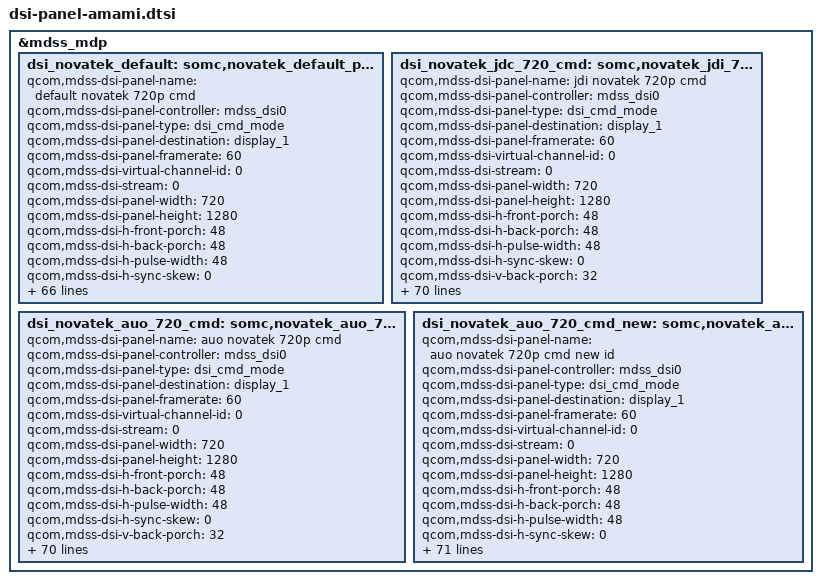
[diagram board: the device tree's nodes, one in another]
/* Copyright (c) 2012, Code Aurora Forum. All rights reserved.
 * Copyright (C) 2013-2014 Sony Mobile Communications AB.
 *
 * This program is free software; you can redistribute it and/or modify
 * it under the terms of the GNU General Public License version 2 and
 * only version 2 as published by the Free Software Foundation.
 *
 * This program is distributed in the hope that it will be useful,
 * but WITHOUT ANY WARRANTY; without even the implied warranty of
 * MERCHANTABILITY or FITNESS FOR A PARTICULAR PURPOSE.  See the
 * GNU General Public License for more details.
 */

&mdss_mdp {
	dsi_novatek_default: somc,novatek_default_panel {
		qcom,mdss-dsi-panel-name = "default novatek 720p cmd";
		qcom,mdss-dsi-panel-controller = <&mdss_dsi0>;
		qcom,mdss-dsi-panel-type = "dsi_cmd_mode";
		qcom,mdss-dsi-panel-destination = "display_1";
		qcom,mdss-dsi-panel-framerate = <60>;
		qcom,mdss-dsi-virtual-channel-id = <0>;
		qcom,mdss-dsi-stream = <0>;
		qcom,mdss-dsi-panel-width = <720>;
		qcom,mdss-dsi-panel-height = <1280>;
		qcom,mdss-dsi-h-front-porch = <48>;
		qcom,mdss-dsi-h-back-porch = <48>;
		qcom,mdss-dsi-h-pulse-width = <48>;
		qcom,mdss-dsi-h-sync-skew = <0>;
		qcom,mdss-dsi-v-back-porch = <32>;
		qcom,mdss-dsi-v-front-porch = <32>;
		qcom,mdss-dsi-v-pulse-width = <32>;
		qcom,mdss-dsi-h-left-border = <0>;
		qcom,mdss-dsi-h-right-border = <0>;
		qcom,mdss-dsi-v-top-border = <0>;
		qcom,mdss-dsi-v-bottom-border = <0>;
		qcom,mdss-dsi-bpp = <24>;
		qcom,mdss-dsi-underflow-color = <0x0>;
		qcom,mdss-dsi-border-color = <0>;
		somc,mdss-dsi-id-read-command = [06 01 00 01 05 00 02 A1 00];
		somc,mdss-dsi-early-init-command = [15 01 00 00 00 00 02 FF EE
				15 01 00 00 01 00 02 26 08
				15 01 00 00 00 00 02 26 00
				15 01 00 00 00 00 02 FF 00];
		somc,mdss-dsi-init-command = [15 01 00 00 00 00 02 BA 03
				15 01 00 00 00 00 02 C2 08
				15 01 00 00 00 00 02 FB 01
				15 01 00 00 00 00 02 FF 01
				15 01 00 00 00 00 02 75 00
				15 01 00 00 00 00 02 76 00
				15 01 00 00 00 00 02 77 00
				15 01 00 00 00 00 02 78 0F
				15 01 00 00 00 00 02 79 00
				15 01 00 00 00 00 02 7A 27
				15 01 00 00 00 00 02 7B 00
				15 01 00 00 00 00 02 7C 38
				15 01 00 00 00 00 02 7D 00
				15 01 00 00 00 00 02 7E 48
				15 01 00 00 00 00 02 7F 00
				15 01 00 00 00 00 02 80 57
				15 01 00 00 00 00 02 81 00
				15 01 00 00 00 00 02 82 64
				15 01 00 00 00 00 02 83 00
				15 01 00 00 00 00 02 84 72
				15 01 00 00 00 00 02 85 00
				15 01 00 00 00 00 02 86 7E
				15 01 00 00 00 00 02 87 00
				15 01 00 00 00 00 02 88 A5
				15 01 00 00 00 00 02 89 00
				15 01 00 00 00 00 02 8A C6
				15 01 00 00 00 00 02 8B 00
				15 01 00 00 00 00 02 8C FD
				15 01 00 00 00 00 02 8D 01
				15 01 00 00 00 00 02 8E 28
				15 01 00 00 00 00 02 8F 01
				15 01 00 00 00 00 02 90 71
				15 01 00 00 00 00 02 91 01
				15 01 00 00 00 00 02 92 AC
				15 01 00 00 00 00 02 93 01
				15 01 00 00 00 00 02 94 AD
				15 01 00 00 00 00 02 95 01
				15 01 00 00 00 00 02 96 E4
				15 01 00 00 00 00 02 97 02
				15 01 00 00 00 00 02 98 33
				15 01 00 00 00 00 02 99 02
				15 01 00 00 00 00 02 9A 75
				15 01 00 00 00 00 02 9B 02
				15 01 00 00 00 00 02 9C D0
				15 01 00 00 00 00 02 9D 03
				15 01 00 00 00 00 02 9E 09
				15 01 00 00 00 00 02 9F 03
				15 01 00 00 00 00 02 A0 33
				15 01 00 00 00 00 02 A2 03
				15 01 00 00 00 00 02 A3 3C
				15 01 00 00 00 00 02 A4 03
				15 01 00 00 00 00 02 A5 47
				15 01 00 00 00 00 02 A6 03
				15 01 00 00 00 00 02 A7 59
				15 01 00 00 00 00 02 A9 03
				15 01 00 00 00 00 02 AA 73
				15 01 00 00 00 00 02 AB 03
				15 01 00 00 00 00 02 AC 97
				15 01 00 00 00 00 02 AD 03
				15 01 00 00 00 00 02 AE BF
				15 01 00 00 00 00 02 AF 03
				15 01 00 00 00 00 02 B0 E9
				15 01 00 00 00 00 02 B1 03
				15 01 00 00 00 00 02 B2 FF
				15 01 00 00 00 00 02 B3 00
				15 01 00 00 00 00 02 B4 00
				15 01 00 00 00 00 02 B5 00
				15 01 00 00 00 00 02 B6 0F
				15 01 00 00 00 00 02 B7 00
				15 01 00 00 00 00 02 B8 27
				15 01 00 00 00 00 02 B9 00
				15 01 00 00 00 00 02 BA 38
				15 01 00 00 00 00 02 BB 00
				15 01 00 00 00 00 02 BC 48
				15 01 00 00 00 00 02 BD 00
				15 01 00 00 00 00 02 BE 57
				15 01 00 00 00 00 02 BF 00
				15 01 00 00 00 00 02 C0 64
				15 01 00 00 00 00 02 C1 00
				15 01 00 00 00 00 02 C2 72
				15 01 00 00 00 00 02 C3 00
				15 01 00 00 00 00 02 C4 7E
				15 01 00 00 00 00 02 C5 00
				15 01 00 00 00 00 02 C6 A5
				15 01 00 00 00 00 02 C7 00
				15 01 00 00 00 00 02 C8 C6
				15 01 00 00 00 00 02 C9 00
				15 01 00 00 00 00 02 CA FD
				15 01 00 00 00 00 02 CB 01
				15 01 00 00 00 00 02 CC 28
				15 01 00 00 00 00 02 CD 01
				15 01 00 00 00 00 02 CE 71
				15 01 00 00 00 00 02 CF 01
				15 01 00 00 00 00 02 D0 AC
				15 01 00 00 00 00 02 D1 01
				15 01 00 00 00 00 02 D2 AD
				15 01 00 00 00 00 02 D3 01
				15 01 00 00 00 00 02 D4 E4
				15 01 00 00 00 00 02 D5 02
				15 01 00 00 00 00 02 D6 33
				15 01 00 00 00 00 02 D7 02
				15 01 00 00 00 00 02 D8 75
				15 01 00 00 00 00 02 D9 02
				15 01 00 00 00 00 02 DA D0
				15 01 00 00 00 00 02 DB 03
				15 01 00 00 00 00 02 DC 09
				15 01 00 00 00 00 02 DD 03
				15 01 00 00 00 00 02 DE 33
				15 01 00 00 00 00 02 DF 03
				15 01 00 00 00 00 02 E0 3C
				15 01 00 00 00 00 02 E1 03
				15 01 00 00 00 00 02 E2 47
				15 01 00 00 00 00 02 E3 03
				15 01 00 00 00 00 02 E4 59
				15 01 00 00 00 00 02 E5 03
				15 01 00 00 00 00 02 E6 73
				15 01 00 00 00 00 02 E7 03
				15 01 00 00 00 00 02 E8 97
				15 01 00 00 00 00 02 E9 03
				15 01 00 00 00 00 02 EA BF
				15 01 00 00 00 00 02 EB 03
				15 01 00 00 00 00 02 EC E9
				15 01 00 00 00 00 02 ED 03
				15 01 00 00 00 00 02 EE FF
				15 01 00 00 00 00 02 EF 00
				15 01 00 00 00 00 02 F0 80
				15 01 00 00 00 00 02 F1 00
				15 01 00 00 00 00 02 F2 84
				15 01 00 00 00 00 02 F3 00
				15 01 00 00 00 00 02 F4 8F
				15 01 00 00 00 00 02 F5 00
				15 01 00 00 00 00 02 F6 98
				15 01 00 00 00 00 02 F7 00
				15 01 00 00 00 00 02 F8 A1
				15 01 00 00 00 00 02 F9 00
				15 01 00 00 00 00 02 FA AA
				15 01 00 00 00 00 02 FF 02
				15 01 00 00 00 00 02 00 00
				15 01 00 00 00 00 02 01 B3
				15 01 00 00 00 00 02 02 00
				15 01 00 00 00 00 02 03 BB
				15 01 00 00 00 00 02 04 00
				15 01 00 00 00 00 02 05 C2
				15 01 00 00 00 00 02 06 00
				15 01 00 00 00 00 02 07 DE
				15 01 00 00 00 00 02 08 00
				15 01 00 00 00 00 02 09 F7
				15 01 00 00 00 00 02 0A 01
				15 01 00 00 00 00 02 0B 22
				15 01 00 00 00 00 02 0C 01
				15 01 00 00 00 00 02 0D 48
				15 01 00 00 00 00 02 0E 01
				15 01 00 00 00 00 02 0F 86
				15 01 00 00 00 00 02 10 01
				15 01 00 00 00 00 02 11 BB
				15 01 00 00 00 00 02 12 01
				15 01 00 00 00 00 02 13 BD
				15 01 00 00 00 00 02 14 01
				15 01 00 00 00 00 02 15 EE
				15 01 00 00 00 00 02 16 02
				15 01 00 00 00 00 02 17 39
				15 01 00 00 00 00 02 18 02
				15 01 00 00 00 00 02 19 79
				15 01 00 00 00 00 02 1A 02
				15 01 00 00 00 00 02 1B CB
				15 01 00 00 00 00 02 1C 03
				15 01 00 00 00 00 02 1D 00
				15 01 00 00 00 00 02 1E 03
				15 01 00 00 00 00 02 1F 2E
				15 01 00 00 00 00 02 20 03
				15 01 00 00 00 00 02 21 3D
				15 01 00 00 00 00 02 22 03
				15 01 00 00 00 00 02 23 4E
				15 01 00 00 00 00 02 24 03
				15 01 00 00 00 00 02 25 62
				15 01 00 00 00 00 02 26 03
				15 01 00 00 00 00 02 27 7A
				15 01 00 00 00 00 02 28 03
				15 01 00 00 00 00 02 29 97
				15 01 00 00 00 00 02 2A 03
				15 01 00 00 00 00 02 2B BB
				15 01 00 00 00 00 02 2D 03
				15 01 00 00 00 00 02 2F E7
				15 01 00 00 00 00 02 30 03
				15 01 00 00 00 00 02 31 FF
				15 01 00 00 00 00 02 32 00
				15 01 00 00 00 00 02 33 80
				15 01 00 00 00 00 02 34 00
				15 01 00 00 00 00 02 35 84
				15 01 00 00 00 00 02 36 00
				15 01 00 00 00 00 02 37 8F
				15 01 00 00 00 00 02 38 00
				15 01 00 00 00 00 02 39 98
				15 01 00 00 00 00 02 3A 00
				15 01 00 00 00 00 02 3B A1
				15 01 00 00 00 00 02 3D 00
				15 01 00 00 00 00 02 3F AA
				15 01 00 00 00 00 02 40 00
				15 01 00 00 00 00 02 41 B3
				15 01 00 00 00 00 02 42 00
				15 01 00 00 00 00 02 43 BB
				15 01 00 00 00 00 02 44 00
				15 01 00 00 00 00 02 45 C2
				15 01 00 00 00 00 02 46 00
				15 01 00 00 00 00 02 47 DE
				15 01 00 00 00 00 02 48 00
				15 01 00 00 00 00 02 49 F7
				15 01 00 00 00 00 02 4A 01
				15 01 00 00 00 00 02 4B 22
				15 01 00 00 00 00 02 4C 01
				15 01 00 00 00 00 02 4D 48
				15 01 00 00 00 00 02 4E 01
				15 01 00 00 00 00 02 4F 86
				15 01 00 00 00 00 02 50 01
				15 01 00 00 00 00 02 51 BB
				15 01 00 00 00 00 02 52 01
				15 01 00 00 00 00 02 53 BD
				15 01 00 00 00 00 02 54 01
				15 01 00 00 00 00 02 55 EE
				15 01 00 00 00 00 02 56 02
				15 01 00 00 00 00 02 58 39
				15 01 00 00 00 00 02 59 02
				15 01 00 00 00 00 02 5A 79
				15 01 00 00 00 00 02 5B 02
				15 01 00 00 00 00 02 5C CB
				15 01 00 00 00 00 02 5D 03
				15 01 00 00 00 00 02 5E 00
				15 01 00 00 00 00 02 5F 03
				15 01 00 00 00 00 02 60 2E
				15 01 00 00 00 00 02 61 03
				15 01 00 00 00 00 02 62 3D
				15 01 00 00 00 00 02 63 03
				15 01 00 00 00 00 02 64 4E
				15 01 00 00 00 00 02 65 03
				15 01 00 00 00 00 02 66 62
				15 01 00 00 00 00 02 67 03
				15 01 00 00 00 00 02 68 7A
				15 01 00 00 00 00 02 69 03
				15 01 00 00 00 00 02 6A 97
				15 01 00 00 00 00 02 6B 03
				15 01 00 00 00 00 02 6C BB
				15 01 00 00 00 00 02 6D 03
				15 01 00 00 00 00 02 6E E7
				15 01 00 00 00 00 02 6F 03
				15 01 00 00 00 00 02 70 FF
				15 01 00 00 00 00 02 71 00
				15 01 00 00 00 00 02 72 00
				15 01 00 00 00 00 02 73 00
				15 01 00 00 00 00 02 74 0E
				15 01 00 00 00 00 02 75 00
				15 01 00 00 00 00 02 76 21
				15 01 00 00 00 00 02 77 00
				15 01 00 00 00 00 02 78 2F
				15 01 00 00 00 00 02 79 00
				15 01 00 00 00 00 02 7A 3E
				15 01 00 00 00 00 02 7B 00
				15 01 00 00 00 00 02 7C 4C
				15 01 00 00 00 00 02 7D 00
				15 01 00 00 00 00 02 7E 5A
				15 01 00 00 00 00 02 7F 00
				15 01 00 00 00 00 02 80 67
				15 01 00 00 00 00 02 81 00
				15 01 00 00 00 00 02 82 71
				15 01 00 00 00 00 02 83 00
				15 01 00 00 00 00 02 84 97
				15 01 00 00 00 00 02 85 00
				15 01 00 00 00 00 02 86 B8
				15 01 00 00 00 00 02 87 00
				15 01 00 00 00 00 02 88 F1
				15 01 00 00 00 00 02 89 01
				15 01 00 00 00 00 02 8A 1C
				15 01 00 00 00 00 02 8B 01
				15 01 00 00 00 00 02 8C 63
				15 01 00 00 00 00 02 8D 01
				15 01 00 00 00 00 02 8E A0
				15 01 00 00 00 00 02 8F 01
				15 01 00 00 00 00 02 90 A1
				15 01 00 00 00 00 02 91 01
				15 01 00 00 00 00 02 92 D6
				15 01 00 00 00 00 02 93 02
				15 01 00 00 00 00 02 94 24
				15 01 00 00 00 00 02 95 02
				15 01 00 00 00 00 02 96 61
				15 01 00 00 00 00 02 97 02
				15 01 00 00 00 00 02 98 B7
				15 01 00 00 00 00 02 99 02
				15 01 00 00 00 00 02 9A F4
				15 01 00 00 00 00 02 9B 03
				15 01 00 00 00 00 02 9C 24
				15 01 00 00 00 00 02 9D 03
				15 01 00 00 00 00 02 9E 36
				15 01 00 00 00 00 02 9F 03
				15 01 00 00 00 00 02 A0 4B
				15 01 00 00 00 00 02 A2 03
				15 01 00 00 00 00 02 A3 63
				15 01 00 00 00 00 02 A4 03
				15 01 00 00 00 00 02 A5 7D
				15 01 00 00 00 00 02 A6 03
				15 01 00 00 00 00 02 A7 9B
				15 01 00 00 00 00 02 A9 03
				15 01 00 00 00 00 02 AA BF
				15 01 00 00 00 00 02 AB 03
				15 01 00 00 00 00 02 AC E8
				15 01 00 00 00 00 02 AD 03
				15 01 00 00 00 00 02 AE FF
				15 01 00 00 00 00 02 AF 00
				15 01 00 00 00 00 02 B0 00
				15 01 00 00 00 00 02 B1 00
				15 01 00 00 00 00 02 B2 0E
				15 01 00 00 00 00 02 B3 00
				15 01 00 00 00 00 02 B4 21
				15 01 00 00 00 00 02 B5 00
				15 01 00 00 00 00 02 B6 2F
				15 01 00 00 00 00 02 B7 00
				15 01 00 00 00 00 02 B8 3E
				15 01 00 00 00 00 02 B9 00
				15 01 00 00 00 00 02 BA 4C
				15 01 00 00 00 00 02 BB 00
				15 01 00 00 00 00 02 BC 5A
				15 01 00 00 00 00 02 BD 00
				15 01 00 00 00 00 02 BE 67
				15 01 00 00 00 00 02 BF 00
				15 01 00 00 00 00 02 C0 71
				15 01 00 00 00 00 02 C1 00
				15 01 00 00 00 00 02 C2 97
				15 01 00 00 00 00 02 C3 00
				15 01 00 00 00 00 02 C4 B8
				15 01 00 00 00 00 02 C5 00
				15 01 00 00 00 00 02 C6 F1
				15 01 00 00 00 00 02 C7 01
				15 01 00 00 00 00 02 C8 1C
				15 01 00 00 00 00 02 C9 01
				15 01 00 00 00 00 02 CA 63
				15 01 00 00 00 00 02 CB 01
				15 01 00 00 00 00 02 CC A0
				15 01 00 00 00 00 02 CD 01
				15 01 00 00 00 00 02 CE A1
				15 01 00 00 00 00 02 CF 01
				15 01 00 00 00 00 02 D0 D6
				15 01 00 00 00 00 02 D1 02
				15 01 00 00 00 00 02 D2 24
				15 01 00 00 00 00 02 D3 02
				15 01 00 00 00 00 02 D4 61
				15 01 00 00 00 00 02 D5 02
				15 01 00 00 00 00 02 D6 B7
				15 01 00 00 00 00 02 D7 02
				15 01 00 00 00 00 02 D8 F4
				15 01 00 00 00 00 02 D9 03
				15 01 00 00 00 00 02 DA 24
				15 01 00 00 00 00 02 DB 03
				15 01 00 00 00 00 02 DC 36
				15 01 00 00 00 00 02 DD 03
				15 01 00 00 00 00 02 DE 4B
				15 01 00 00 00 00 02 DF 03
				15 01 00 00 00 00 02 E0 63
				15 01 00 00 00 00 02 E1 03
				15 01 00 00 00 00 02 E2 7D
				15 01 00 00 00 00 02 E3 03
				15 01 00 00 00 00 02 E4 9B
				15 01 00 00 00 00 02 E5 03
				15 01 00 00 00 00 02 E6 BF
				15 01 00 00 00 00 02 E7 03
				15 01 00 00 00 00 02 E8 E8
				15 01 00 00 00 00 02 E9 03
				15 01 00 00 00 00 02 EA FF
				15 01 00 00 00 00 02 FF 01
				15 01 00 00 00 00 02 FB 01
				15 01 00 00 00 00 02 FF 02
				15 01 00 00 00 00 02 FB 01
				15 01 00 00 00 00 02 FF EE
				15 01 00 00 00 00 02 12 50
				15 01 00 00 00 00 02 13 02
				15 01 00 00 00 00 02 6A 60
				15 01 00 00 00 00 02 FB 01
				15 01 00 00 00 00 02 FF 00
				15 01 00 00 0A 00 02 35 00
				05 01 00 00 00 00 01 11];
		qcom,mdss-dsi-on-command = [05 01 00 00 00 00 01 29];
		qcom,mdss-dsi-off-command = [05 01 00 00 00 00 01 28
				05 01 00 00 78 00 01 10];
		qcom,mdss-dsi-on-command-state = "dsi_hs_mode";
		qcom,mdss-dsi-off-command-state = "dsi_hs_mode";

		somc,mdss-dsi-cabc-early-on-command = [15 01 00 00 00 00 02 FF 04
				15 01 00 00 00 00 02 2A 84
				15 01 00 00 00 00 02 29 99
				15 01 00 00 00 00 02 28 99
				15 01 00 00 00 00 02 27 99
				15 01 00 00 00 00 02 26 AA
				15 01 00 00 00 00 02 25 BB
				15 01 00 00 00 00 02 24 CC
				15 01 00 00 00 00 02 23 DD
				15 01 00 00 00 00 02 22 EE
				15 01 00 00 00 00 02 21 FF
				15 01 00 00 00 00 02 0A 03
				15 01 00 00 00 00 02 32 64
				15 01 00 00 00 00 02 FB 01
				15 01 00 00 00 00 02 FF 00
				15 01 00 00 00 00 02 51 FF
				15 01 00 00 00 00 02 53 2C
				15 01 00 00 00 00 02 55 03];
		somc,mdss-dsi-cabc-late-off-command = [15 01 00 00 00 00 02 51 00
				15 01 00 00 00 00 02 53 00
				15 01 00 00 00 00 02 55 00];
		somc,mdss-dsi-cabc-enabled = <1>;

		qcom,mdss-dsi-h-sync-pulse = <1>;
		qcom,mdss-dsi-traffic-mode = "non_burst_sync_event";
		qcom,mdss-dsi-bllp-eof-power-mode;
		qcom,mdss-dsi-bllp-power-mode;
		qcom,mdss-dsi-lane-0-state;
		qcom,mdss-dsi-lane-1-state;
		qcom,mdss-dsi-lane-2-state;
		qcom,mdss-dsi-lane-3-state;
		qcom,mdss-dsi-te-pin-select = <1>;
		qcom,mdss-dsi-te-v-sync-rd-ptr-irq-line = <0x2c>;
		qcom,mdss-dsi-te-v-sync-continue-lines = <0x3c>;
		qcom,mdss-dsi-te-dcs-command = <1>;
		qcom,mdss-dsi-te-check-enable;
		qcom,mdss-dsi-te-using-te-pin;
		qcom,mdss-dsi-panel-timings = [7a 1a 12 00 3e 42 16 20 14 03 04 00];
		qcom,mdss-dsi-t-clk-post = <0x0c>;
		qcom,mdss-dsi-t-clk-pre = <0x1a>;
		qcom,mdss-dsi-bl-min-level = <1>;
		qcom,mdss-dsi-bl-max-level = <4095>;
		qcom,mdss-dsi-dma-trigger = "trigger_sw";
		qcom,mdss-dsi-mdp-trigger = "none";
		qcom,mdss-dsi-bl-pmic-control-type = "bl_ctrl_wled";
		qcom,mdss-dsi-pan-enable-dynamic-fps;
		qcom,mdss-dsi-pan-fps-update = "dfps_suspend_resume_mode";
		qcom,mdss-dsi-reset-sequence = <1 20>, <0 200>, <1 20>;

		qcom,mdss-dsi-panel-clockrate = <428000000>;
		somc,panel-id = [ff];
		somc,panel-detect = <1>;
		somc,driver-ic = <2>;
		somc,mdss-phy-size-mm = <53 94>;
		somc,mdss-dsi-lane-config = [00 c2 45 00 00 00 00 01 75
				00 c2 45 00 00 00 00 01 75
				00 c2 45 00 00 00 00 01 75
				00 c2 45 00 00 00 00 01 75
				00 02 45 00 00 00 00 01 97];
		somc,mdss-dsi-disp-on-in-hs = <0>;
		somc,mdss-dsi-init-from-begin = <1>;
	};

	dsi_novatek_jdc_720_cmd: somc,novatek_jdi_720p_panel {
		qcom,mdss-dsi-panel-name = "jdi novatek 720p cmd";
		qcom,mdss-dsi-panel-controller = <&mdss_dsi0>;
		qcom,mdss-dsi-panel-type = "dsi_cmd_mode";
		qcom,mdss-dsi-panel-destination = "display_1";
		qcom,mdss-dsi-panel-framerate = <60>;
		qcom,mdss-dsi-virtual-channel-id = <0>;
		qcom,mdss-dsi-stream = <0>;
		qcom,mdss-dsi-panel-width = <720>;
		qcom,mdss-dsi-panel-height = <1280>;
		qcom,mdss-dsi-h-front-porch = <48>;
		qcom,mdss-dsi-h-back-porch = <48>;
		qcom,mdss-dsi-h-pulse-width = <48>;
		qcom,mdss-dsi-h-sync-skew = <0>;
		qcom,mdss-dsi-v-back-porch = <32>;
		qcom,mdss-dsi-v-front-porch = <32>;
		qcom,mdss-dsi-v-pulse-width = <32>;
		qcom,mdss-dsi-h-left-border = <0>;
		qcom,mdss-dsi-h-right-border = <0>;
		qcom,mdss-dsi-v-top-border = <0>;
		qcom,mdss-dsi-v-bottom-border = <0>;
		qcom,mdss-dsi-bpp = <24>;
		qcom,mdss-dsi-underflow-color = <0x0>;
		qcom,mdss-dsi-border-color = <0>;
		somc,mdss-dsi-id-read-command = [06 01 00 01 05 00 02 A1 00];
		somc,mdss-dsi-early-init-command = [15 01 00 00 00 00 02 FF EE
				15 01 00 00 01 00 02 26 08
				15 01 00 00 00 00 02 26 00
				15 01 00 00 00 00 02 FF 00];
		somc,mdss-dsi-init-command = [15 01 00 00 00 00 02 BA 03
				15 01 00 00 00 00 02 C2 08
				15 01 00 00 00 00 02 FB 01
				15 01 00 00 00 00 02 FF 01
				15 01 00 00 00 00 02 75 00
				15 01 00 00 00 00 02 76 00
				15 01 00 00 00 00 02 77 00
				15 01 00 00 00 00 02 78 0F
				15 01 00 00 00 00 02 79 00
				15 01 00 00 00 00 02 7A 27
				15 01 00 00 00 00 02 7B 00
				15 01 00 00 00 00 02 7C 38
				15 01 00 00 00 00 02 7D 00
				15 01 00 00 00 00 02 7E 48
				15 01 00 00 00 00 02 7F 00
				15 01 00 00 00 00 02 80 57
				15 01 00 00 00 00 02 81 00
				15 01 00 00 00 00 02 82 64
				15 01 00 00 00 00 02 83 00
				15 01 00 00 00 00 02 84 72
				15 01 00 00 00 00 02 85 00
				15 01 00 00 00 00 02 86 7E
				15 01 00 00 00 00 02 87 00
				15 01 00 00 00 00 02 88 A5
				15 01 00 00 00 00 02 89 00
				15 01 00 00 00 00 02 8A C6
				15 01 00 00 00 00 02 8B 00
				15 01 00 00 00 00 02 8C FD
				15 01 00 00 00 00 02 8D 01
				15 01 00 00 00 00 02 8E 28
				15 01 00 00 00 00 02 8F 01
				15 01 00 00 00 00 02 90 71
				15 01 00 00 00 00 02 91 01
				15 01 00 00 00 00 02 92 AC
				15 01 00 00 00 00 02 93 01
				15 01 00 00 00 00 02 94 AD
				15 01 00 00 00 00 02 95 01
				15 01 00 00 00 00 02 96 E4
				15 01 00 00 00 00 02 97 02
				15 01 00 00 00 00 02 98 33
				15 01 00 00 00 00 02 99 02
				15 01 00 00 00 00 02 9A 75
				15 01 00 00 00 00 02 9B 02
				15 01 00 00 00 00 02 9C D0
				15 01 00 00 00 00 02 9D 03
				15 01 00 00 00 00 02 9E 09
				15 01 00 00 00 00 02 9F 03
				15 01 00 00 00 00 02 A0 33
				15 01 00 00 00 00 02 A2 03
				15 01 00 00 00 00 02 A3 3C
				15 01 00 00 00 00 02 A4 03
				15 01 00 00 00 00 02 A5 47
				15 01 00 00 00 00 02 A6 03
				15 01 00 00 00 00 02 A7 59
				15 01 00 00 00 00 02 A9 03
				15 01 00 00 00 00 02 AA 73
				15 01 00 00 00 00 02 AB 03
				15 01 00 00 00 00 02 AC 97
				15 01 00 00 00 00 02 AD 03
				15 01 00 00 00 00 02 AE BF
				15 01 00 00 00 00 02 AF 03
				15 01 00 00 00 00 02 B0 E9
				15 01 00 00 00 00 02 B1 03
				15 01 00 00 00 00 02 B2 FF
				15 01 00 00 00 00 02 B3 00
				15 01 00 00 00 00 02 B4 00
				15 01 00 00 00 00 02 B5 00
				15 01 00 00 00 00 02 B6 0F
				15 01 00 00 00 00 02 B7 00
				15 01 00 00 00 00 02 B8 27
				15 01 00 00 00 00 02 B9 00
				15 01 00 00 00 00 02 BA 38
				15 01 00 00 00 00 02 BB 00
				15 01 00 00 00 00 02 BC 48
				15 01 00 00 00 00 02 BD 00
				15 01 00 00 00 00 02 BE 57
				15 01 00 00 00 00 02 BF 00
				15 01 00 00 00 00 02 C0 64
				15 01 00 00 00 00 02 C1 00
				15 01 00 00 00 00 02 C2 72
				15 01 00 00 00 00 02 C3 00
				15 01 00 00 00 00 02 C4 7E
				15 01 00 00 00 00 02 C5 00
				15 01 00 00 00 00 02 C6 A5
				15 01 00 00 00 00 02 C7 00
				15 01 00 00 00 00 02 C8 C6
				15 01 00 00 00 00 02 C9 00
				15 01 00 00 00 00 02 CA FD
				15 01 00 00 00 00 02 CB 01
				15 01 00 00 00 00 02 CC 28
				15 01 00 00 00 00 02 CD 01
				15 01 00 00 00 00 02 CE 71
				15 01 00 00 00 00 02 CF 01
				15 01 00 00 00 00 02 D0 AC
				15 01 00 00 00 00 02 D1 01
				15 01 00 00 00 00 02 D2 AD
				15 01 00 00 00 00 02 D3 01
				15 01 00 00 00 00 02 D4 E4
				15 01 00 00 00 00 02 D5 02
				15 01 00 00 00 00 02 D6 33
				15 01 00 00 00 00 02 D7 02
				15 01 00 00 00 00 02 D8 75
				15 01 00 00 00 00 02 D9 02
				15 01 00 00 00 00 02 DA D0
				15 01 00 00 00 00 02 DB 03
				15 01 00 00 00 00 02 DC 09
				15 01 00 00 00 00 02 DD 03
				15 01 00 00 00 00 02 DE 33
				15 01 00 00 00 00 02 DF 03
				15 01 00 00 00 00 02 E0 3C
				15 01 00 00 00 00 02 E1 03
				15 01 00 00 00 00 02 E2 47
				15 01 00 00 00 00 02 E3 03
				15 01 00 00 00 00 02 E4 59
				15 01 00 00 00 00 02 E5 03
				15 01 00 00 00 00 02 E6 73
				15 01 00 00 00 00 02 E7 03
				15 01 00 00 00 00 02 E8 97
				15 01 00 00 00 00 02 E9 03
				15 01 00 00 00 00 02 EA BF
				15 01 00 00 00 00 02 EB 03
				15 01 00 00 00 00 02 EC E9
				15 01 00 00 00 00 02 ED 03
				15 01 00 00 00 00 02 EE FF
				15 01 00 00 00 00 02 EF 00
				15 01 00 00 00 00 02 F0 80
				15 01 00 00 00 00 02 F1 00
				15 01 00 00 00 00 02 F2 84
				15 01 00 00 00 00 02 F3 00
				15 01 00 00 00 00 02 F4 8F
				15 01 00 00 00 00 02 F5 00
				15 01 00 00 00 00 02 F6 98
				15 01 00 00 00 00 02 F7 00
				15 01 00 00 00 00 02 F8 A1
				15 01 00 00 00 00 02 F9 00
				15 01 00 00 00 00 02 FA AA
				15 01 00 00 00 00 02 FF 02
				15 01 00 00 00 00 02 00 00
				15 01 00 00 00 00 02 01 B3
				15 01 00 00 00 00 02 02 00
				15 01 00 00 00 00 02 03 BB
				15 01 00 00 00 00 02 04 00
				15 01 00 00 00 00 02 05 C2
				15 01 00 00 00 00 02 06 00
				15 01 00 00 00 00 02 07 DE
				15 01 00 00 00 00 02 08 00
				15 01 00 00 00 00 02 09 F7
				15 01 00 00 00 00 02 0A 01
				15 01 00 00 00 00 02 0B 22
				15 01 00 00 00 00 02 0C 01
				15 01 00 00 00 00 02 0D 48
				15 01 00 00 00 00 02 0E 01
				15 01 00 00 00 00 02 0F 86
				15 01 00 00 00 00 02 10 01
				15 01 00 00 00 00 02 11 BB
				15 01 00 00 00 00 02 12 01
				15 01 00 00 00 00 02 13 BD
				15 01 00 00 00 00 02 14 01
				15 01 00 00 00 00 02 15 EE
				15 01 00 00 00 00 02 16 02
				15 01 00 00 00 00 02 17 39
				15 01 00 00 00 00 02 18 02
				15 01 00 00 00 00 02 19 79
				15 01 00 00 00 00 02 1A 02
				15 01 00 00 00 00 02 1B CB
				15 01 00 00 00 00 02 1C 03
				15 01 00 00 00 00 02 1D 00
				15 01 00 00 00 00 02 1E 03
				15 01 00 00 00 00 02 1F 2E
				15 01 00 00 00 00 02 20 03
				15 01 00 00 00 00 02 21 3D
				15 01 00 00 00 00 02 22 03
				15 01 00 00 00 00 02 23 4E
				15 01 00 00 00 00 02 24 03
				15 01 00 00 00 00 02 25 62
				15 01 00 00 00 00 02 26 03
				15 01 00 00 00 00 02 27 7A
				15 01 00 00 00 00 02 28 03
				15 01 00 00 00 00 02 29 97
				15 01 00 00 00 00 02 2A 03
				15 01 00 00 00 00 02 2B BB
				15 01 00 00 00 00 02 2D 03
				15 01 00 00 00 00 02 2F E7
				15 01 00 00 00 00 02 30 03
				15 01 00 00 00 00 02 31 FF
				15 01 00 00 00 00 02 32 00
				15 01 00 00 00 00 02 33 80
				15 01 00 00 00 00 02 34 00
				15 01 00 00 00 00 02 35 84
				15 01 00 00 00 00 02 36 00
				15 01 00 00 00 00 02 37 8F
				15 01 00 00 00 00 02 38 00
				15 01 00 00 00 00 02 39 98
				15 01 00 00 00 00 02 3A 00
				15 01 00 00 00 00 02 3B A1
				15 01 00 00 00 00 02 3D 00
				15 01 00 00 00 00 02 3F AA
				15 01 00 00 00 00 02 40 00
				15 01 00 00 00 00 02 41 B3
				15 01 00 00 00 00 02 42 00
				15 01 00 00 00 00 02 43 BB
				15 01 00 00 00 00 02 44 00
				15 01 00 00 00 00 02 45 C2
				15 01 00 00 00 00 02 46 00
				15 01 00 00 00 00 02 47 DE
				15 01 00 00 00 00 02 48 00
				15 01 00 00 00 00 02 49 F7
				15 01 00 00 00 00 02 4A 01
				15 01 00 00 00 00 02 4B 22
				15 01 00 00 00 00 02 4C 01
				15 01 00 00 00 00 02 4D 48
				15 01 00 00 00 00 02 4E 01
				15 01 00 00 00 00 02 4F 86
				15 01 00 00 00 00 02 50 01
				15 01 00 00 00 00 02 51 BB
				15 01 00 00 00 00 02 52 01
				15 01 00 00 00 00 02 53 BD
				15 01 00 00 00 00 02 54 01
				15 01 00 00 00 00 02 55 EE
				15 01 00 00 00 00 02 56 02
				15 01 00 00 00 00 02 58 39
				15 01 00 00 00 00 02 59 02
				15 01 00 00 00 00 02 5A 79
				15 01 00 00 00 00 02 5B 02
				15 01 00 00 00 00 02 5C CB
				15 01 00 00 00 00 02 5D 03
				15 01 00 00 00 00 02 5E 00
				15 01 00 00 00 00 02 5F 03
				15 01 00 00 00 00 02 60 2E
				15 01 00 00 00 00 02 61 03
				15 01 00 00 00 00 02 62 3D
				15 01 00 00 00 00 02 63 03
				15 01 00 00 00 00 02 64 4E
				15 01 00 00 00 00 02 65 03
				15 01 00 00 00 00 02 66 62
				15 01 00 00 00 00 02 67 03
				15 01 00 00 00 00 02 68 7A
				15 01 00 00 00 00 02 69 03
				15 01 00 00 00 00 02 6A 97
				15 01 00 00 00 00 02 6B 03
				15 01 00 00 00 00 02 6C BB
				15 01 00 00 00 00 02 6D 03
				15 01 00 00 00 00 02 6E E7
				15 01 00 00 00 00 02 6F 03
				15 01 00 00 00 00 02 70 FF
				15 01 00 00 00 00 02 71 00
				15 01 00 00 00 00 02 72 00
				15 01 00 00 00 00 02 73 00
				15 01 00 00 00 00 02 74 0E
				15 01 00 00 00 00 02 75 00
				15 01 00 00 00 00 02 76 21
				15 01 00 00 00 00 02 77 00
				15 01 00 00 00 00 02 78 2F
				15 01 00 00 00 00 02 79 00
				15 01 00 00 00 00 02 7A 3E
				15 01 00 00 00 00 02 7B 00
				15 01 00 00 00 00 02 7C 4C
				15 01 00 00 00 00 02 7D 00
				15 01 00 00 00 00 02 7E 5A
				15 01 00 00 00 00 02 7F 00
				15 01 00 00 00 00 02 80 67
				15 01 00 00 00 00 02 81 00
				15 01 00 00 00 00 02 82 71
				15 01 00 00 00 00 02 83 00
				15 01 00 00 00 00 02 84 97
				15 01 00 00 00 00 02 85 00
				15 01 00 00 00 00 02 86 B8
				15 01 00 00 00 00 02 87 00
				15 01 00 00 00 00 02 88 F1
				15 01 00 00 00 00 02 89 01
				15 01 00 00 00 00 02 8A 1C
				15 01 00 00 00 00 02 8B 01
				15 01 00 00 00 00 02 8C 63
				15 01 00 00 00 00 02 8D 01
				15 01 00 00 00 00 02 8E A0
				15 01 00 00 00 00 02 8F 01
				15 01 00 00 00 00 02 90 A1
				15 01 00 00 00 00 02 91 01
				15 01 00 00 00 00 02 92 D6
				15 01 00 00 00 00 02 93 02
				15 01 00 00 00 00 02 94 24
				15 01 00 00 00 00 02 95 02
				15 01 00 00 00 00 02 96 61
				15 01 00 00 00 00 02 97 02
				15 01 00 00 00 00 02 98 B7
				15 01 00 00 00 00 02 99 02
				15 01 00 00 00 00 02 9A F4
				15 01 00 00 00 00 02 9B 03
				15 01 00 00 00 00 02 9C 24
				15 01 00 00 00 00 02 9D 03
				15 01 00 00 00 00 02 9E 36
				15 01 00 00 00 00 02 9F 03
				15 01 00 00 00 00 02 A0 4B
				15 01 00 00 00 00 02 A2 03
				15 01 00 00 00 00 02 A3 63
				15 01 00 00 00 00 02 A4 03
				15 01 00 00 00 00 02 A5 7D
				15 01 00 00 00 00 02 A6 03
				15 01 00 00 00 00 02 A7 9B
				15 01 00 00 00 00 02 A9 03
				15 01 00 00 00 00 02 AA BF
				15 01 00 00 00 00 02 AB 03
				15 01 00 00 00 00 02 AC E8
				15 01 00 00 00 00 02 AD 03
				15 01 00 00 00 00 02 AE FF
				15 01 00 00 00 00 02 AF 00
				15 01 00 00 00 00 02 B0 00
				15 01 00 00 00 00 02 B1 00
				15 01 00 00 00 00 02 B2 0E
				15 01 00 00 00 00 02 B3 00
				15 01 00 00 00 00 02 B4 21
				15 01 00 00 00 00 02 B5 00
				15 01 00 00 00 00 02 B6 2F
				15 01 00 00 00 00 02 B7 00
				15 01 00 00 00 00 02 B8 3E
				15 01 00 00 00 00 02 B9 00
				15 01 00 00 00 00 02 BA 4C
				15 01 00 00 00 00 02 BB 00
				15 01 00 00 00 00 02 BC 5A
				15 01 00 00 00 00 02 BD 00
				15 01 00 00 00 00 02 BE 67
				15 01 00 00 00 00 02 BF 00
				15 01 00 00 00 00 02 C0 71
				15 01 00 00 00 00 02 C1 00
				15 01 00 00 00 00 02 C2 97
				15 01 00 00 00 00 02 C3 00
				15 01 00 00 00 00 02 C4 B8
				15 01 00 00 00 00 02 C5 00
				15 01 00 00 00 00 02 C6 F1
				15 01 00 00 00 00 02 C7 01
				15 01 00 00 00 00 02 C8 1C
				15 01 00 00 00 00 02 C9 01
				15 01 00 00 00 00 02 CA 63
				15 01 00 00 00 00 02 CB 01
				15 01 00 00 00 00 02 CC A0
				15 01 00 00 00 00 02 CD 01
				15 01 00 00 00 00 02 CE A1
				15 01 00 00 00 00 02 CF 01
				15 01 00 00 00 00 02 D0 D6
				15 01 00 00 00 00 02 D1 02
				15 01 00 00 00 00 02 D2 24
				15 01 00 00 00 00 02 D3 02
				15 01 00 00 00 00 02 D4 61
				15 01 00 00 00 00 02 D5 02
				15 01 00 00 00 00 02 D6 B7
				15 01 00 00 00 00 02 D7 02
				15 01 00 00 00 00 02 D8 F4
				15 01 00 00 00 00 02 D9 03
				15 01 00 00 00 00 02 DA 24
				15 01 00 00 00 00 02 DB 03
				15 01 00 00 00 00 02 DC 36
				15 01 00 00 00 00 02 DD 03
				15 01 00 00 00 00 02 DE 4B
				15 01 00 00 00 00 02 DF 03
				15 01 00 00 00 00 02 E0 63
				15 01 00 00 00 00 02 E1 03
				15 01 00 00 00 00 02 E2 7D
				15 01 00 00 00 00 02 E3 03
				15 01 00 00 00 00 02 E4 9B
				15 01 00 00 00 00 02 E5 03
				15 01 00 00 00 00 02 E6 BF
				15 01 00 00 00 00 02 E7 03
				15 01 00 00 00 00 02 E8 E8
				15 01 00 00 00 00 02 E9 03
				15 01 00 00 00 00 02 EA FF
				15 01 00 00 00 00 02 FF 01
				15 01 00 00 00 00 02 FB 01
				15 01 00 00 00 00 02 FF 02
				15 01 00 00 00 00 02 FB 01
				15 01 00 00 00 00 02 FF EE
				15 01 00 00 00 00 02 12 50
				15 01 00 00 00 00 02 13 02
				15 01 00 00 00 00 02 6A 60
				15 01 00 00 00 00 02 FB 01
				15 01 00 00 00 00 02 FF 00
				15 01 00 00 0A 00 02 35 00
				05 01 00 00 00 00 01 11];
		qcom,mdss-dsi-on-command = [05 01 00 00 00 00 01 29];
		qcom,mdss-dsi-off-command = [05 01 00 00 00 00 01 28
				05 01 00 00 78 00 01 10];
		qcom,mdss-dsi-on-command-state = "dsi_hs_mode";
		qcom,mdss-dsi-off-command-state = "dsi_hs_mode";

		somc,mdss-dsi-cabc-early-on-command = [15 01 00 00 00 00 02 FF 04
				15 01 00 00 00 00 02 2A 84
				15 01 00 00 00 00 02 29 99
				15 01 00 00 00 00 02 28 99
				15 01 00 00 00 00 02 27 99
				15 01 00 00 00 00 02 26 AA
				15 01 00 00 00 00 02 25 BB
				15 01 00 00 00 00 02 24 CC
				15 01 00 00 00 00 02 23 DD
				15 01 00 00 00 00 02 22 EE
				15 01 00 00 00 00 02 21 FF
				15 01 00 00 00 00 02 0A 03
				15 01 00 00 00 00 02 32 64
				15 01 00 00 00 00 02 FB 01
				15 01 00 00 00 00 02 FF 00
				15 01 00 00 00 00 02 51 FF
				15 01 00 00 00 00 02 53 2C
				15 01 00 00 00 00 02 55 03];
		somc,mdss-dsi-cabc-late-off-command = [15 01 00 00 00 00 02 51 00
				15 01 00 00 00 00 02 53 00
				15 01 00 00 00 00 02 55 00];
		somc,mdss-dsi-cabc-enabled = <1>;

		qcom,mdss-dsi-h-sync-pulse = <1>;
		qcom,mdss-dsi-traffic-mode = "non_burst_sync_event";
		qcom,mdss-dsi-bllp-eof-power-mode;
		qcom,mdss-dsi-bllp-power-mode;
		qcom,mdss-dsi-lane-0-state;
		qcom,mdss-dsi-lane-1-state;
		qcom,mdss-dsi-lane-2-state;
		qcom,mdss-dsi-lane-3-state;
		qcom,mdss-dsi-te-pin-select = <1>;
		qcom,mdss-dsi-te-v-sync-rd-ptr-irq-line = <0x2c>;
		qcom,mdss-dsi-te-v-sync-continue-lines = <0x3c>;
		qcom,mdss-dsi-te-dcs-command = <1>;
		qcom,mdss-dsi-te-check-enable;
		qcom,mdss-dsi-te-using-te-pin;
		qcom,mdss-dsi-panel-timings = [7a 1a 12 00 3e 42 16 20 14 03 04 00];
		qcom,mdss-dsi-t-clk-post = <0x0c>;
		qcom,mdss-dsi-t-clk-pre = <0x1a>;
		qcom,mdss-dsi-bl-min-level = <1>;
		qcom,mdss-dsi-bl-max-level = <4095>;
		qcom,mdss-dsi-dma-trigger = "trigger_sw";
		qcom,mdss-dsi-mdp-trigger = "none";
		qcom,mdss-dsi-bl-pmic-control-type = "bl_ctrl_wled";
		qcom,mdss-dsi-pan-enable-dynamic-fps;
		qcom,mdss-dsi-pan-fps-update = "dfps_suspend_resume_mode";
		qcom,mdss-dsi-reset-sequence = <1 20>, <0 200>, <1 20>;

		qcom,mdss-dsi-panel-clockrate = <428000000>;
		somc,panel-id = [ff ff ff 57];
		somc,driver-ic = <2>;
		somc,mdss-phy-size-mm = <53 94>;
		somc,mdss-dsi-lane-config = [00 c2 45 00 00 00 00 01 75
				00 c2 45 00 00 00 00 01 75
				00 c2 45 00 00 00 00 01 75
				00 c2 45 00 00 00 00 01 75
				00 02 45 00 00 00 00 01 97];
		somc,mdss-dsi-disp-on-in-hs = <0>;
		somc,mdss-dsi-init-from-begin = <1>;

		somc,mdss-dsi-uv-command = [04 01 00 00 00 00 01 DA
				04 01 00 00 00 00 01 DB];
		somc,mdss-dsi-uv-param-type = <4>;
		somc,mdss-dsi-pcc-table-size = <58>;
		somc,mdss-dsi-pcc-table = <
				0x00 0x01 0x24 0x27 0x30 0x33 0x6800 0x6f80 0x8000
				0x00 0x02 0x28 0x2B 0x30 0x33 0x6500 0x7100 0x8000
				0x00 0x03 0x18 0x1B 0x2C 0x2F 0x7600 0x7400 0x8000
				0x00 0x04 0x1C 0x1F 0x2C 0x2F 0x7480 0x7580 0x8000
				0x00 0x05 0x20 0x23 0x2C 0x2F 0x7280 0x7500 0x8000
				0x00 0x06 0x24 0x27 0x2C 0x2F 0x6d80 0x7500 0x8000
				0x00 0x07 0x28 0x2B 0x2C 0x2F 0x6780 0x7300 0x8000
				0x00 0x08 0x18 0x1B 0x28 0x2B 0x7a00 0x7680 0x8000
				0x00 0x09 0x1C 0x1F 0x28 0x2B 0x7900 0x7800 0x8000
				0x00 0x0A 0x20 0x23 0x28 0x2B 0x7180 0x7800 0x8000
				0x00 0x0B 0x24 0x27 0x28 0x2B 0x6f00 0x7880 0x8000
				0x00 0x0C 0x28 0x2B 0x28 0x2B 0x6c00 0x7800 0x8000
				0x00 0x0D 0x18 0x1B 0x24 0x27 0x7d80 0x7980 0x8000
				0x00 0x0E 0x1C 0x1F 0x24 0x27 0x7b80 0x7b00 0x8000
				0x00 0x0F 0x20 0x23 0x24 0x27 0x7600 0x7d00 0x8000
				0x00 0x10 0x24 0x27 0x24 0x27 0x7180 0x7b00 0x8000
				0x00 0x11 0x28 0x2B 0x24 0x27 0x7000 0x7d00 0x8000
				0x00 0x12 0x14 0x17 0x20 0x23 0x8000 0x7980 0x7d00
				0x00 0x13 0x18 0x1B 0x20 0x23 0x7f00 0x7b00 0x7d80
				0x00 0x14 0x1C 0x1F 0x20 0x23 0x7c00 0x7c00 0x7c80
				0x00 0x15 0x20 0x23 0x20 0x23 0x7100 0x7b00 0x7d00
				0x00 0x16 0x24 0x27 0x20 0x23 0x7280 0x7d00 0x7e80
				0x00 0x17 0x28 0x2B 0x20 0x23 0x7000 0x7d00 0x7e80
				0x00 0x18 0x14 0x17 0x1C 0x1F 0x8000 0x7800 0x7900
				0x00 0x19 0x18 0x1B 0x1C 0x1F 0x8000 0x7c00 0x7c00
				0xFF 0x00 0x1C 0x1F 0x1C 0x1F 0x8000 0x8000 0x8000
				0x00 0x1A 0x20 0x23 0x1C 0x1F 0x7a80 0x8000 0x7e80
				0x00 0x1B 0x24 0x27 0x1C 0x1F 0x7680 0x8000 0x7d80
				0x00 0x1C 0x28 0x2B 0x1C 0x1F 0x7300 0x8000 0x7f00
				0x00 0x1D 0x14 0x17 0x18 0x1B 0x8000 0x7800 0x7580
				0x00 0x1E 0x18 0x1B 0x18 0x1B 0x8000 0x7b00 0x7780
				0x00 0x1F 0x1C 0x1F 0x18 0x1B 0x8000 0x8000 0x7c80
				0x00 0x20 0x20 0x23 0x18 0x1B 0x7900 0x8000 0x7980
				0x00 0x21 0x14 0x17 0x14 0x17 0x8000 0x7880 0x7480
				0x00 0x22 0x18 0x1B 0x14 0x17 0x8000 0x7c00 0x7600
				0x00 0x25 0x14 0x17 0x24 0x27 0x8000 0x7400 0x7c80
				0x00 0x26 0x14 0x17 0x28 0x33 0x7880 0x6e00 0x8000
				0x00 0x27 0x18 0x23 0x30 0x33 0x6b80 0x6b00 0x7e00
				0x00 0x28 0x14 0x27 0x34 0x3C 0x6080 0x5f80 0x7780
				0x00 0x29 0x28 0x2B 0x34 0x3C 0x5880 0x6500 0x7c80
				0x00 0x2A 0x28 0x2B 0x14 0x1B 0x5500 0x6600 0x5e80
				0x00 0x2B 0x24 0x27 0x18 0x1B 0x7500 0x8000 0x7200
				0x00 0x2C 0x1C 0x1F 0x14 0x17 0x8000 0x8000 0x7900
				0x00 0x2D 0x20 0x23 0x14 0x17 0x7a80 0x8000 0x7800
				0x00 0x2E 0x24 0x27 0x14 0x17 0x7580 0x8000 0x7780
				0x00 0x2F 0x18 0x1B 0x10 0x13 0x8000 0x7980 0x6f80
				0x00 0x30 0x1C 0x1F 0x10 0x13 0x8000 0x7f80 0x7500
				0x00 0x31 0x20 0x23 0x10 0x13 0x7a80 0x8000 0x7500
				0x00 0x32 0x24 0x27 0x10 0x13 0x7500 0x8000 0x7400
				0x01 0x00 0x00 0x13 0x28 0x3C 0x7c00 0x5f80 0x7380
				0xFF 0x00 0x14 0x27 0x28 0x3C 0x8000 0x8000 0x8000
				0x02 0x00 0x28 0x3C 0x28 0x3C 0x5100 0x6600 0x7380
				0x03 0x00 0x00 0x13 0x14 0x27 0x7d80 0x5f80 0x6300
				0xFF 0x00 0x14 0x27 0x14 0x27 0x8000 0x8000 0x8000
				0x04 0x00 0x28 0x3C 0x14 0x27 0x4e00 0x6600 0x6100
				0x05 0x00 0x00 0x13 0x00 0x13 0x7d00 0x5f00 0x5680
				0x06 0x00 0x14 0x27 0x00 0x13 0x7d80 0x8000 0x6f80
				0x07 0x00 0x28 0x3C 0x00 0x13 0x4d00 0x6600 0x5280>;
	};

	dsi_novatek_auo_720_cmd: somc,novatek_auo_720p_panel {
		qcom,mdss-dsi-panel-name = "auo novatek 720p cmd";
		qcom,mdss-dsi-panel-controller = <&mdss_dsi0>;
		qcom,mdss-dsi-panel-type = "dsi_cmd_mode";
		qcom,mdss-dsi-panel-destination = "display_1";
		qcom,mdss-dsi-panel-framerate = <60>;
		qcom,mdss-dsi-virtual-channel-id = <0>;
		qcom,mdss-dsi-stream = <0>;
		qcom,mdss-dsi-panel-width = <720>;
		qcom,mdss-dsi-panel-height = <1280>;
		qcom,mdss-dsi-h-front-porch = <48>;
		qcom,mdss-dsi-h-back-porch = <48>;
		qcom,mdss-dsi-h-pulse-width = <48>;
		qcom,mdss-dsi-h-sync-skew = <0>;
		qcom,mdss-dsi-v-back-porch = <32>;
		qcom,mdss-dsi-v-front-porch = <32>;
		qcom,mdss-dsi-v-pulse-width = <32>;
		qcom,mdss-dsi-h-left-border = <0>;
		qcom,mdss-dsi-h-right-border = <0>;
		qcom,mdss-dsi-v-top-border = <0>;
		qcom,mdss-dsi-v-bottom-border = <0>;
		qcom,mdss-dsi-bpp = <24>;
		qcom,mdss-dsi-underflow-color = <0x0>;
		qcom,mdss-dsi-border-color = <0>;
		somc,mdss-dsi-id-read-command = [06 01 00 01 05 00 02 A1 00];
		somc,mdss-dsi-early-init-command = [15 01 00 00 00 00 02 FF EE
				15 01 00 00 01 00 02 26 08
				15 01 00 00 00 00 02 26 00
				15 01 00 00 00 00 02 FF 00];
		somc,mdss-dsi-init-command = [15 01 00 00 00 00 02 FF EE
				15 01 00 00 00 00 02 FB 01
				15 01 00 00 00 00 02 12 50
				15 01 00 00 00 00 02 13 02
				15 01 00 00 00 00 02 FF 00
				15 01 00 00 00 00 02 FF 01
				15 01 00 00 00 00 02 FB 01
				15 01 00 00 00 00 02 00 4A
				15 01 00 00 00 00 02 01 43
				15 01 00 00 00 00 02 02 54
				15 01 00 00 00 00 02 03 55
				15 01 00 00 00 00 02 04 55
				15 01 00 00 00 00 02 05 33
				15 01 00 00 00 00 02 06 22
				15 01 00 00 00 00 02 08 56
				15 01 00 00 00 00 02 09 8F
				15 01 00 00 00 00 02 0B 97
				15 01 00 00 00 00 02 0C 97
				15 01 00 00 00 00 02 0D 2F
				15 01 00 00 00 00 02 0E 24
				15 01 00 00 00 00 02 36 73
				15 01 00 00 00 00 02 0F 04
				15 01 00 00 00 00 02 69 99
				15 01 00 00 00 00 02 6F 03
				15 01 00 00 00 00 02 FF 05
				15 01 00 00 00 00 02 FB 01
				15 01 00 00 00 00 02 01 00
				15 01 00 00 00 00 02 02 8D
				15 01 00 00 00 00 02 03 8D
				15 01 00 00 00 00 02 04 8D
				15 01 00 00 00 00 02 05 30
				15 01 00 00 00 00 02 06 33
				15 01 00 00 00 00 02 07 01
				15 01 00 00 00 00 02 08 00
				15 01 00 00 00 00 02 09 46
				15 01 00 00 00 00 02 0A 46
				15 01 00 00 00 00 02 0D 0B
				15 01 00 00 00 00 02 0E 1D
				15 01 00 00 00 00 02 0F 08
				15 01 00 00 00 00 02 10 53
				15 01 00 00 00 00 02 11 00
				15 01 00 00 00 00 02 12 00
				15 01 00 00 00 00 02 14 01
				15 01 00 00 00 00 02 15 00
				15 01 00 00 00 00 02 16 05
				15 01 00 00 00 00 02 17 04
				15 01 00 00 00 00 02 19 7F
				15 01 00 00 00 00 02 1A FF
				15 01 00 00 00 00 02 1B 0F
				15 01 00 00 00 00 02 1C 00
				15 01 00 00 00 00 02 1D 00
				15 01 00 00 00 00 02 1E 00
				15 01 00 00 00 00 02 1F 07
				15 01 00 00 00 00 02 20 00
				15 01 00 00 00 00 02 21 00
				15 01 00 00 00 00 02 22 55
				15 01 00 00 00 00 02 23 4D
				15 01 00 00 00 00 02 6C 00
				15 01 00 00 00 00 02 6D 00
				15 01 00 00 00 00 02 2D 02
				15 01 00 00 00 00 02 83 02
				15 01 00 00 00 00 02 9E 58
				15 01 00 00 00 00 02 9F 58
				15 01 00 00 00 00 02 A0 41
				15 01 00 00 00 00 02 A2 10
				15 01 00 00 00 00 02 BB 0A
				15 01 00 00 00 00 02 BC 0A
				15 01 00 00 00 00 02 28 01
				15 01 00 00 00 00 02 2F 02
				15 01 00 00 00 00 02 32 08
				15 01 00 00 00 00 02 33 B8
				15 01 00 00 00 00 02 36 02
				15 01 00 00 00 00 02 37 00
				15 01 00 00 00 00 02 43 00
				15 01 00 00 00 00 02 4B 21
				15 01 00 00 00 00 02 4C 03
				15 01 00 00 00 00 02 50 21
				15 01 00 00 00 00 02 51 03
				15 01 00 00 00 00 02 58 21
				15 01 00 00 00 00 02 59 03
				15 01 00 00 00 00 02 5D 21
				15 01 00 00 00 00 02 5E 03
				15 01 00 00 00 00 02 FF 01
				15 01 00 00 00 00 02 FB 01
				15 01 00 00 00 00 02 75 00
				15 01 00 00 00 00 02 76 59
				15 01 00 00 00 00 02 77 00
				15 01 00 00 00 00 02 78 61
				15 01 00 00 00 00 02 79 00
				15 01 00 00 00 00 02 7A 72
				15 01 00 00 00 00 02 7B 00
				15 01 00 00 00 00 02 7C 81
				15 01 00 00 00 00 02 7D 00
				15 01 00 00 00 00 02 7E 90
				15 01 00 00 00 00 02 7F 00
				15 01 00 00 00 00 02 80 9E
				15 01 00 00 00 00 02 81 00
				15 01 00 00 00 00 02 82 AB
				15 01 00 00 00 00 02 83 00
				15 01 00 00 00 00 02 84 B7
				15 01 00 00 00 00 02 85 00
				15 01 00 00 00 00 02 86 C2
				15 01 00 00 00 00 02 87 00
				15 01 00 00 00 00 02 88 E8
				15 01 00 00 00 00 02 89 01
				15 01 00 00 00 00 02 8A 0A
				15 01 00 00 00 00 02 8B 01
				15 01 00 00 00 00 02 8C 40
				15 01 00 00 00 00 02 8D 01
				15 01 00 00 00 00 02 8E 6E
				15 01 00 00 00 00 02 8F 01
				15 01 00 00 00 00 02 90 B5
				15 01 00 00 00 00 02 91 02
				15 01 00 00 00 00 02 92 0D
				15 01 00 00 00 00 02 93 02
				15 01 00 00 00 00 02 94 0F
				15 01 00 00 00 00 02 95 02
				15 01 00 00 00 00 02 96 57
				15 01 00 00 00 00 02 97 02
				15 01 00 00 00 00 02 98 9E
				15 01 00 00 00 00 02 99 02
				15 01 00 00 00 00 02 9A CA
				15 01 00 00 00 00 02 9B 03
				15 01 00 00 00 00 02 9C 05
				15 01 00 00 00 00 02 9D 03
				15 01 00 00 00 00 02 9E 2C
				15 01 00 00 00 00 02 9F 03
				15 01 00 00 00 00 02 A0 60
				15 01 00 00 00 00 02 A2 03
				15 01 00 00 00 00 02 A3 71
				15 01 00 00 00 00 02 A4 03
				15 01 00 00 00 00 02 A5 87
				15 01 00 00 00 00 02 A6 03
				15 01 00 00 00 00 02 A7 B8
				15 01 00 00 00 00 02 A9 03
				15 01 00 00 00 00 02 AA C8
				15 01 00 00 00 00 02 AB 03
				15 01 00 00 00 00 02 AC D8
				15 01 00 00 00 00 02 AD 03
				15 01 00 00 00 00 02 AE E8
				15 01 00 00 00 00 02 AF 03
				15 01 00 00 00 00 02 B0 F8
				15 01 00 00 00 00 02 B1 03
				15 01 00 00 00 00 02 B2 FF
				15 01 00 00 00 00 02 B3 00
				15 01 00 00 00 00 02 B4 59
				15 01 00 00 00 00 02 B5 00
				15 01 00 00 00 00 02 B6 61
				15 01 00 00 00 00 02 B7 00
				15 01 00 00 00 00 02 B8 72
				15 01 00 00 00 00 02 B9 00
				15 01 00 00 00 00 02 BA 81
				15 01 00 00 00 00 02 BB 00
				15 01 00 00 00 00 02 BC 90
				15 01 00 00 00 00 02 BD 00
				15 01 00 00 00 00 02 BE 9E
				15 01 00 00 00 00 02 BF 00
				15 01 00 00 00 00 02 C0 AB
				15 01 00 00 00 00 02 C1 00
				15 01 00 00 00 00 02 C2 B7
				15 01 00 00 00 00 02 C3 00
				15 01 00 00 00 00 02 C4 C2
				15 01 00 00 00 00 02 C5 00
				15 01 00 00 00 00 02 C6 E8
				15 01 00 00 00 00 02 C7 01
				15 01 00 00 00 00 02 C8 0A
				15 01 00 00 00 00 02 C9 01
				15 01 00 00 00 00 02 CA 40
				15 01 00 00 00 00 02 CB 01
				15 01 00 00 00 00 02 CC 6E
				15 01 00 00 00 00 02 CD 01
				15 01 00 00 00 00 02 CE B5
				15 01 00 00 00 00 02 CF 02
				15 01 00 00 00 00 02 D0 0D
				15 01 00 00 00 00 02 D1 02
				15 01 00 00 00 00 02 D2 0F
				15 01 00 00 00 00 02 D3 02
				15 01 00 00 00 00 02 D4 57
				15 01 00 00 00 00 02 D5 02
				15 01 00 00 00 00 02 D6 9E
				15 01 00 00 00 00 02 D7 02
				15 01 00 00 00 00 02 D8 CA
				15 01 00 00 00 00 02 D9 03
				15 01 00 00 00 00 02 DA 05
				15 01 00 00 00 00 02 DB 03
				15 01 00 00 00 00 02 DC 2C
				15 01 00 00 00 00 02 DD 03
				15 01 00 00 00 00 02 DE 60
				15 01 00 00 00 00 02 DF 03
				15 01 00 00 00 00 02 E0 71
				15 01 00 00 00 00 02 E1 03
				15 01 00 00 00 00 02 E2 87
				15 01 00 00 00 00 02 E3 03
				15 01 00 00 00 00 02 E4 B8
				15 01 00 00 00 00 02 E5 03
				15 01 00 00 00 00 02 E6 C8
				15 01 00 00 00 00 02 E7 03
				15 01 00 00 00 00 02 E8 D8
				15 01 00 00 00 00 02 E9 03
				15 01 00 00 00 00 02 EA E8
				15 01 00 00 00 00 02 EB 03
				15 01 00 00 00 00 02 EC F8
				15 01 00 00 00 00 02 ED 03
				15 01 00 00 00 00 02 EE FF
				15 01 00 00 00 00 02 EF 00
				15 01 00 00 00 00 02 F0 6E
				15 01 00 00 00 00 02 F1 00
				15 01 00 00 00 00 02 F2 76
				15 01 00 00 00 00 02 F3 00
				15 01 00 00 00 00 02 F4 85
				15 01 00 00 00 00 02 F5 00
				15 01 00 00 00 00 02 F6 92
				15 01 00 00 00 00 02 F7 00
				15 01 00 00 00 00 02 F8 9F
				15 01 00 00 00 00 02 F9 00
				15 01 00 00 00 00 02 FA AB
				15 01 00 00 00 00 02 FF 02
				15 01 00 00 00 00 02 FB 01
				15 01 00 00 00 00 02 00 00
				15 01 00 00 00 00 02 01 B6
				15 01 00 00 00 00 02 02 00
				15 01 00 00 00 00 02 03 C1
				15 01 00 00 00 00 02 04 00
				15 01 00 00 00 00 02 05 CB
				15 01 00 00 00 00 02 06 00
				15 01 00 00 00 00 02 07 EF
				15 01 00 00 00 00 02 08 01
				15 01 00 00 00 00 02 09 0F
				15 01 00 00 00 00 02 0A 01
				15 01 00 00 00 00 02 0B 43
				15 01 00 00 00 00 02 0C 01
				15 01 00 00 00 00 02 0D 6E
				15 01 00 00 00 00 02 0E 01
				15 01 00 00 00 00 02 0F B4
				15 01 00 00 00 00 02 10 02
				15 01 00 00 00 00 02 11 0C
				15 01 00 00 00 00 02 12 02
				15 01 00 00 00 00 02 13 0E
				15 01 00 00 00 00 02 14 02
				15 01 00 00 00 00 02 15 56
				15 01 00 00 00 00 02 16 02
				15 01 00 00 00 00 02 17 9E
				15 01 00 00 00 00 02 18 02
				15 01 00 00 00 00 02 19 CA
				15 01 00 00 00 00 02 1A 03
				15 01 00 00 00 00 02 1B 05
				15 01 00 00 00 00 02 1C 03
				15 01 00 00 00 00 02 1D 2A
				15 01 00 00 00 00 02 1E 03
				15 01 00 00 00 00 02 1F 56
				15 01 00 00 00 00 02 20 03
				15 01 00 00 00 00 02 21 61
				15 01 00 00 00 00 02 22 03
				15 01 00 00 00 00 02 23 6F
				15 01 00 00 00 00 02 24 03
				15 01 00 00 00 00 02 25 7D
				15 01 00 00 00 00 02 26 03
				15 01 00 00 00 00 02 27 8D
				15 01 00 00 00 00 02 28 03
				15 01 00 00 00 00 02 29 96
				15 01 00 00 00 00 02 2A 03
				15 01 00 00 00 00 02 2B A2
				15 01 00 00 00 00 02 2D 03
				15 01 00 00 00 00 02 2F B4
				15 01 00 00 00 00 02 30 03
				15 01 00 00 00 00 02 31 FF
				15 01 00 00 00 00 02 32 00
				15 01 00 00 00 00 02 33 6E
				15 01 00 00 00 00 02 34 00
				15 01 00 00 00 00 02 35 76
				15 01 00 00 00 00 02 36 00
				15 01 00 00 00 00 02 37 85
				15 01 00 00 00 00 02 38 00
				15 01 00 00 00 00 02 39 92
				15 01 00 00 00 00 02 3A 00
				15 01 00 00 00 00 02 3B 9F
				15 01 00 00 00 00 02 3D 00
				15 01 00 00 00 00 02 3F AB
				15 01 00 00 00 00 02 40 00
				15 01 00 00 00 00 02 41 B6
				15 01 00 00 00 00 02 42 00
				15 01 00 00 00 00 02 43 C1
				15 01 00 00 00 00 02 44 00
				15 01 00 00 00 00 02 45 CB
				15 01 00 00 00 00 02 46 00
				15 01 00 00 00 00 02 47 EF
				15 01 00 00 00 00 02 48 01
				15 01 00 00 00 00 02 49 0F
				15 01 00 00 00 00 02 4A 01
				15 01 00 00 00 00 02 4B 43
				15 01 00 00 00 00 02 4C 01
				15 01 00 00 00 00 02 4D 6E
				15 01 00 00 00 00 02 4E 01
				15 01 00 00 00 00 02 4F B4
				15 01 00 00 00 00 02 50 02
				15 01 00 00 00 00 02 51 0C
				15 01 00 00 00 00 02 52 02
				15 01 00 00 00 00 02 53 0E
				15 01 00 00 00 00 02 54 02
				15 01 00 00 00 00 02 55 56
				15 01 00 00 00 00 02 56 02
				15 01 00 00 00 00 02 58 9E
				15 01 00 00 00 00 02 59 02
				15 01 00 00 00 00 02 5A CA
				15 01 00 00 00 00 02 5B 03
				15 01 00 00 00 00 02 5C 05
				15 01 00 00 00 00 02 5D 03
				15 01 00 00 00 00 02 5E 2A
				15 01 00 00 00 00 02 5F 03
				15 01 00 00 00 00 02 60 56
				15 01 00 00 00 00 02 61 03
				15 01 00 00 00 00 02 62 61
				15 01 00 00 00 00 02 63 03
				15 01 00 00 00 00 02 64 6F
				15 01 00 00 00 00 02 65 03
				15 01 00 00 00 00 02 66 7D
				15 01 00 00 00 00 02 67 03
				15 01 00 00 00 00 02 68 8D
				15 01 00 00 00 00 02 69 03
				15 01 00 00 00 00 02 6A 96
				15 01 00 00 00 00 02 6B 03
				15 01 00 00 00 00 02 6C A2
				15 01 00 00 00 00 02 6D 03
				15 01 00 00 00 00 02 6E B4
				15 01 00 00 00 00 02 6F 03
				15 01 00 00 00 00 02 70 FF
				15 01 00 00 00 00 02 71 00
				15 01 00 00 00 00 02 72 00
				15 01 00 00 00 00 02 73 00
				15 01 00 00 00 00 02 74 0E
				15 01 00 00 00 00 02 75 00
				15 01 00 00 00 00 02 76 26
				15 01 00 00 00 00 02 77 00
				15 01 00 00 00 00 02 78 3A
				15 01 00 00 00 00 02 79 00
				15 01 00 00 00 00 02 7A 4C
				15 01 00 00 00 00 02 7B 00
				15 01 00 00 00 00 02 7C 5E
				15 01 00 00 00 00 02 7D 00
				15 01 00 00 00 00 02 7E 6E
				15 01 00 00 00 00 02 7F 00
				15 01 00 00 00 00 02 80 7B
				15 01 00 00 00 00 02 81 00
				15 01 00 00 00 00 02 82 88
				15 01 00 00 00 00 02 83 00
				15 01 00 00 00 00 02 84 B4
				15 01 00 00 00 00 02 85 00
				15 01 00 00 00 00 02 86 DB
				15 01 00 00 00 00 02 87 01
				15 01 00 00 00 00 02 88 17
				15 01 00 00 00 00 02 89 01
				15 01 00 00 00 00 02 8A 4A
				15 01 00 00 00 00 02 8B 01
				15 01 00 00 00 00 02 8C 98
				15 01 00 00 00 00 02 8D 01
				15 01 00 00 00 00 02 8E FC
				15 01 00 00 00 00 02 8F 01
				15 01 00 00 00 00 02 90 FE
				15 01 00 00 00 00 02 91 02
				15 01 00 00 00 00 02 92 4A
				15 01 00 00 00 00 02 93 02
				15 01 00 00 00 00 02 94 93
				15 01 00 00 00 00 02 95 02
				15 01 00 00 00 00 02 96 C0
				15 01 00 00 00 00 02 97 03
				15 01 00 00 00 00 02 98 01
				15 01 00 00 00 00 02 99 03
				15 01 00 00 00 00 02 9A 2F
				15 01 00 00 00 00 02 9B 03
				15 01 00 00 00 00 02 9C 85
				15 01 00 00 00 00 02 9D 03
				15 01 00 00 00 00 02 9E CC
				15 01 00 00 00 00 02 9F 03
				15 01 00 00 00 00 02 A0 D4
				15 01 00 00 00 00 02 A2 03
				15 01 00 00 00 00 02 A3 DC
				15 01 00 00 00 00 02 A4 03
				15 01 00 00 00 00 02 A5 E4
				15 01 00 00 00 00 02 A6 03
				15 01 00 00 00 00 02 A7 EC
				15 01 00 00 00 00 02 A9 03
				15 01 00 00 00 00 02 AA F4
				15 01 00 00 00 00 02 AB 03
				15 01 00 00 00 00 02 AC FC
				15 01 00 00 00 00 02 AD 03
				15 01 00 00 00 00 02 AE FF
				15 01 00 00 00 00 02 AF 00
				15 01 00 00 00 00 02 B0 00
				15 01 00 00 00 00 02 B1 00
				15 01 00 00 00 00 02 B2 0E
				15 01 00 00 00 00 02 B3 00
				15 01 00 00 00 00 02 B4 26
				15 01 00 00 00 00 02 B5 00
				15 01 00 00 00 00 02 B6 3A
				15 01 00 00 00 00 02 B7 00
				15 01 00 00 00 00 02 B8 4C
				15 01 00 00 00 00 02 B9 00
				15 01 00 00 00 00 02 BA 5E
				15 01 00 00 00 00 02 BB 00
				15 01 00 00 00 00 02 BC 6E
				15 01 00 00 00 00 02 BD 00
				15 01 00 00 00 00 02 BE 7B
				15 01 00 00 00 00 02 BF 00
				15 01 00 00 00 00 02 C0 88
				15 01 00 00 00 00 02 C1 00
				15 01 00 00 00 00 02 C2 B4
				15 01 00 00 00 00 02 C3 00
				15 01 00 00 00 00 02 C4 DB
				15 01 00 00 00 00 02 C5 01
				15 01 00 00 00 00 02 C6 17
				15 01 00 00 00 00 02 C7 01
				15 01 00 00 00 00 02 C8 4A
				15 01 00 00 00 00 02 C9 01
				15 01 00 00 00 00 02 CA 98
				15 01 00 00 00 00 02 CB 01
				15 01 00 00 00 00 02 CC FC
				15 01 00 00 00 00 02 CD 01
				15 01 00 00 00 00 02 CE FE
				15 01 00 00 00 00 02 CF 02
				15 01 00 00 00 00 02 D0 4A
				15 01 00 00 00 00 02 D1 02
				15 01 00 00 00 00 02 D2 93
				15 01 00 00 00 00 02 D3 02
				15 01 00 00 00 00 02 D4 C0
				15 01 00 00 00 00 02 D5 03
				15 01 00 00 00 00 02 D6 01
				15 01 00 00 00 00 02 D7 03
				15 01 00 00 00 00 02 D8 2F
				15 01 00 00 00 00 02 D9 03
				15 01 00 00 00 00 02 DA 85
				15 01 00 00 00 00 02 DB 03
				15 01 00 00 00 00 02 DC CC
				15 01 00 00 00 00 02 DD 03
				15 01 00 00 00 00 02 DE D4
				15 01 00 00 00 00 02 DF 03
				15 01 00 00 00 00 02 E0 DC
				15 01 00 00 00 00 02 E1 03
				15 01 00 00 00 00 02 E2 E4
				15 01 00 00 00 00 02 E3 03
				15 01 00 00 00 00 02 E4 EC
				15 01 00 00 00 00 02 E5 03
				15 01 00 00 00 00 02 E6 F4
				15 01 00 00 00 00 02 E7 03
				15 01 00 00 00 00 02 E8 FC
				15 01 00 00 00 00 02 E9 03
				15 01 00 00 00 00 02 EA FF
				15 01 00 00 00 00 02 FF 00
				15 01 00 00 00 00 02 FB 01
				15 01 00 00 00 00 02 C2 08
				15 01 00 00 00 00 02 BA 03
				15 01 00 00 0A 00 02 35 00
				05 01 00 00 32 00 01 11];
		qcom,mdss-dsi-on-command = [05 01 00 00 00 00 01 29];
		qcom,mdss-dsi-off-command = [05 01 00 00 00 00 01 28
				05 01 00 00 78 00 01 10];
		qcom,mdss-dsi-on-command-state = "dsi_hs_mode";
		qcom,mdss-dsi-off-command-state = "dsi_hs_mode";

		somc,mdss-dsi-cabc-early-on-command = [15 01 00 00 00 00 02 FF 04
				15 01 00 00 00 00 02 2A 84
				15 01 00 00 00 00 02 29 99
				15 01 00 00 00 00 02 28 99
				15 01 00 00 00 00 02 27 99
				15 01 00 00 00 00 02 26 AA
				15 01 00 00 00 00 02 25 BB
				15 01 00 00 00 00 02 24 CC
				15 01 00 00 00 00 02 23 DD
				15 01 00 00 00 00 02 22 EE
				15 01 00 00 00 00 02 21 FF
				15 01 00 00 00 00 02 0A 03
				15 01 00 00 00 00 02 32 64
				15 01 00 00 00 00 02 FB 01
				15 01 00 00 00 00 02 FF 00
				15 01 00 00 00 00 02 51 FF
				15 01 00 00 00 00 02 53 2C
				15 01 00 00 00 00 02 55 03];
		somc,mdss-dsi-cabc-late-off-command = [15 01 00 00 00 00 02 51 00
				15 01 00 00 00 00 02 53 00
				15 01 00 00 00 00 02 55 00];
		somc,mdss-dsi-cabc-enabled = <1>;

		qcom,mdss-dsi-h-sync-pulse = <1>;
		qcom,mdss-dsi-traffic-mode = "non_burst_sync_event";
		qcom,mdss-dsi-bllp-eof-power-mode;
		qcom,mdss-dsi-bllp-power-mode;
		qcom,mdss-dsi-lane-0-state;
		qcom,mdss-dsi-lane-1-state;
		qcom,mdss-dsi-lane-2-state;
		qcom,mdss-dsi-lane-3-state;
		qcom,mdss-dsi-te-pin-select = <1>;
		qcom,mdss-dsi-te-v-sync-rd-ptr-irq-line = <0x2c>;
		qcom,mdss-dsi-te-v-sync-continue-lines = <0x3c>;
		qcom,mdss-dsi-te-dcs-command = <1>;
		qcom,mdss-dsi-te-check-enable;
		qcom,mdss-dsi-te-using-te-pin;
		qcom,mdss-dsi-panel-timings = [7a 1a 12 00 3e 42 16 20 14 03 04 00];
		qcom,mdss-dsi-t-clk-post = <0x0c>;
		qcom,mdss-dsi-t-clk-pre = <0x1a>;
		qcom,mdss-dsi-bl-min-level = <1>;
		qcom,mdss-dsi-bl-max-level = <4095>;
		qcom,mdss-dsi-dma-trigger = "trigger_sw";
		qcom,mdss-dsi-mdp-trigger = "none";
		qcom,mdss-dsi-bl-pmic-control-type = "bl_ctrl_wled";
		qcom,mdss-dsi-pan-enable-dynamic-fps;
		qcom,mdss-dsi-pan-fps-update = "dfps_suspend_resume_mode";
		qcom,mdss-dsi-reset-sequence = <1 20>, <0 200>, <1 20>;

		qcom,mdss-dsi-panel-clockrate = <428000000>;
		somc,panel-id = [ff ff ff 00];
		somc,driver-ic = <2>;
		somc,mdss-phy-size-mm = <53 94>;
		somc,mdss-dsi-lane-config = [00 c2 45 00 00 00 00 01 75
				00 c2 45 00 00 00 00 01 75
				00 c2 45 00 00 00 00 01 75
				00 c2 45 00 00 00 00 01 75
				00 02 45 00 00 00 00 01 97];
		somc,mdss-dsi-disp-on-in-hs = <0>;
		somc,mdss-dsi-init-from-begin = <1>;

		somc,mdss-dsi-uv-command = [04 01 00 00 00 00 01 DA
				04 01 00 00 00 00 01 DB];
		somc,mdss-dsi-uv-param-type = <4>;
		somc,mdss-dsi-pcc-table-size = <58>;
		somc,mdss-dsi-pcc-table = <
				0x00 0x01 0x24 0x27 0x30 0x33 0x6800 0x6f80 0x8000
				0x00 0x02 0x28 0x2B 0x30 0x33 0x6500 0x7100 0x8000
				0x00 0x03 0x18 0x1B 0x2C 0x2F 0x7600 0x7400 0x8000
				0x00 0x04 0x1C 0x1F 0x2C 0x2F 0x7480 0x7580 0x8000
				0x00 0x05 0x20 0x23 0x2C 0x2F 0x7280 0x7500 0x8000
				0x00 0x06 0x24 0x27 0x2C 0x2F 0x6d80 0x7500 0x8000
				0x00 0x07 0x28 0x2B 0x2C 0x2F 0x6780 0x7300 0x8000
				0x00 0x08 0x18 0x1B 0x28 0x2B 0x7a00 0x7680 0x8000
				0x00 0x09 0x1C 0x1F 0x28 0x2B 0x7900 0x7800 0x8000
				0x00 0x0A 0x20 0x23 0x28 0x2B 0x7180 0x7800 0x8000
				0x00 0x0B 0x24 0x27 0x28 0x2B 0x6f00 0x7880 0x8000
				0x00 0x0C 0x28 0x2B 0x28 0x2B 0x6c00 0x7800 0x8000
				0x00 0x0D 0x18 0x1B 0x24 0x27 0x7d80 0x7980 0x8000
				0x00 0x0E 0x1C 0x1F 0x24 0x27 0x7b80 0x7b00 0x8000
				0x00 0x0F 0x20 0x23 0x24 0x27 0x7600 0x7d00 0x8000
				0x00 0x10 0x24 0x27 0x24 0x27 0x7180 0x7b00 0x8000
				0x00 0x11 0x28 0x2B 0x24 0x27 0x7000 0x7d00 0x8000
				0x00 0x12 0x14 0x17 0x20 0x23 0x8000 0x7980 0x7d00
				0x00 0x13 0x18 0x1B 0x20 0x23 0x7f00 0x7b00 0x7d80
				0x00 0x14 0x1C 0x1F 0x20 0x23 0x7c00 0x7c00 0x7c80
				0x00 0x15 0x20 0x23 0x20 0x23 0x7100 0x7b00 0x7d00
				0x00 0x16 0x24 0x27 0x20 0x23 0x7280 0x7d00 0x7e80
				0x00 0x17 0x28 0x2B 0x20 0x23 0x7000 0x7d00 0x7e80
				0x00 0x18 0x14 0x17 0x1C 0x1F 0x8000 0x7800 0x7900
				0x00 0x19 0x18 0x1B 0x1C 0x1F 0x8000 0x7c00 0x7c00
				0xFF 0x00 0x1C 0x1F 0x1C 0x1F 0x8000 0x8000 0x8000
				0x00 0x1A 0x20 0x23 0x1C 0x1F 0x7a80 0x8000 0x7e80
				0x00 0x1B 0x24 0x27 0x1C 0x1F 0x7680 0x8000 0x7d80
				0x00 0x1C 0x28 0x2B 0x1C 0x1F 0x7300 0x8000 0x7f00
				0x00 0x1D 0x14 0x17 0x18 0x1B 0x8000 0x7800 0x7580
				0x00 0x1E 0x18 0x1B 0x18 0x1B 0x8000 0x7b00 0x7780
				0x00 0x1F 0x1C 0x1F 0x18 0x1B 0x8000 0x8000 0x7c80
				0x00 0x20 0x20 0x23 0x18 0x1B 0x7900 0x8000 0x7980
				0x00 0x21 0x14 0x17 0x14 0x17 0x8000 0x7880 0x7480
				0x00 0x22 0x18 0x1B 0x14 0x17 0x8000 0x7c00 0x7600
				0x00 0x25 0x14 0x17 0x24 0x27 0x8000 0x7400 0x7c80
				0x00 0x26 0x14 0x17 0x28 0x33 0x7880 0x6e00 0x8000
				0x00 0x27 0x18 0x23 0x30 0x33 0x6b80 0x6b00 0x7e00
				0x00 0x28 0x14 0x27 0x34 0x3C 0x6080 0x5f80 0x7780
				0x00 0x29 0x28 0x2B 0x34 0x3C 0x5880 0x6500 0x7c80
				0x00 0x2A 0x28 0x2B 0x14 0x1B 0x5500 0x6600 0x5e80
				0x00 0x2B 0x24 0x27 0x18 0x1B 0x7500 0x8000 0x7200
				0x00 0x2C 0x1C 0x1F 0x14 0x17 0x8000 0x8000 0x7900
				0x00 0x2D 0x20 0x23 0x14 0x17 0x7a80 0x8000 0x7800
				0x00 0x2E 0x24 0x27 0x14 0x17 0x7580 0x8000 0x7780
				0x00 0x2F 0x18 0x1B 0x10 0x13 0x8000 0x7980 0x6f80
				0x00 0x30 0x1C 0x1F 0x10 0x13 0x8000 0x7f80 0x7500
				0x00 0x31 0x20 0x23 0x10 0x13 0x7a80 0x8000 0x7500
				0x00 0x32 0x24 0x27 0x10 0x13 0x7500 0x8000 0x7400
				0x01 0x00 0x00 0x13 0x28 0x3C 0x7c00 0x5f80 0x7380
				0xFF 0x00 0x14 0x27 0x28 0x3C 0x8000 0x8000 0x8000
				0x02 0x00 0x28 0x3C 0x28 0x3C 0x5100 0x6600 0x7380
				0x03 0x00 0x00 0x13 0x14 0x27 0x7d80 0x5f80 0x6300
				0xFF 0x00 0x14 0x27 0x14 0x27 0x8000 0x8000 0x8000
				0x04 0x00 0x28 0x3C 0x14 0x27 0x4e00 0x6600 0x6100
				0x05 0x00 0x00 0x13 0x00 0x13 0x7d00 0x5f00 0x5680
				0x06 0x00 0x14 0x27 0x00 0x13 0x7d80 0x8000 0x6f80
				0x07 0x00 0x28 0x3C 0x00 0x13 0x4d00 0x6600 0x5280>;
	};

	dsi_novatek_auo_720_cmd_new: somc,novatek_auo_720p_panel_new_id {
		qcom,mdss-dsi-panel-name = "auo novatek 720p cmd new id";
		qcom,mdss-dsi-panel-controller = <&mdss_dsi0>;
		qcom,mdss-dsi-panel-type = "dsi_cmd_mode";
		qcom,mdss-dsi-panel-destination = "display_1";
		qcom,mdss-dsi-panel-framerate = <60>;
		qcom,mdss-dsi-virtual-channel-id = <0>;
		qcom,mdss-dsi-stream = <0>;
		qcom,mdss-dsi-panel-width = <720>;
		qcom,mdss-dsi-panel-height = <1280>;
		qcom,mdss-dsi-h-front-porch = <48>;
		qcom,mdss-dsi-h-back-porch = <48>;
		qcom,mdss-dsi-h-pulse-width = <48>;
		qcom,mdss-dsi-h-sync-skew = <0>;
		qcom,mdss-dsi-v-back-porch = <32>;
		qcom,mdss-dsi-v-front-porch = <32>;
		qcom,mdss-dsi-v-pulse-width = <32>;
		qcom,mdss-dsi-h-left-border = <0>;
		qcom,mdss-dsi-h-right-border = <0>;
		qcom,mdss-dsi-v-top-border = <0>;
		qcom,mdss-dsi-v-bottom-border = <0>;
		qcom,mdss-dsi-bpp = <24>;
		qcom,mdss-dsi-underflow-color = <0x0>;
		qcom,mdss-dsi-border-color = <0>;
		somc,mdss-dsi-id-read-command = [06 01 00 01 05 00 02 A1 00];
		somc,mdss-dsi-early-init-command = [15 01 00 00 00 00 02 FF EE
				15 01 00 00 01 00 02 26 08
				15 01 00 00 00 00 02 26 00
				15 01 00 00 00 00 02 FF 00];
		somc,mdss-dsi-init-command = [15 01 00 00 00 00 02 FF EE
				15 01 00 00 00 00 02 FB 01
				15 01 00 00 00 00 02 12 50
				15 01 00 00 00 00 02 13 02
				15 01 00 00 00 00 02 FF 00
				15 01 00 00 00 00 02 FF 01
				15 01 00 00 00 00 02 FB 01
				15 01 00 00 00 00 02 00 4A
				15 01 00 00 00 00 02 01 43
				15 01 00 00 00 00 02 02 54
				15 01 00 00 00 00 02 03 55
				15 01 00 00 00 00 02 04 55
				15 01 00 00 00 00 02 05 33
				15 01 00 00 00 00 02 06 22
				15 01 00 00 00 00 02 08 56
				15 01 00 00 00 00 02 09 8F
				15 01 00 00 00 00 02 0B 97
				15 01 00 00 00 00 02 0C 97
				15 01 00 00 00 00 02 0D 2F
				15 01 00 00 00 00 02 0E 24
				15 01 00 00 00 00 02 36 73
				15 01 00 00 00 00 02 0F 04
				15 01 00 00 00 00 02 69 99
				15 01 00 00 00 00 02 6F 03
				15 01 00 00 00 00 02 FF 05
				15 01 00 00 00 00 02 FB 01
				15 01 00 00 00 00 02 01 00
				15 01 00 00 00 00 02 02 8D
				15 01 00 00 00 00 02 03 8D
				15 01 00 00 00 00 02 04 8D
				15 01 00 00 00 00 02 05 30
				15 01 00 00 00 00 02 06 33
				15 01 00 00 00 00 02 07 01
				15 01 00 00 00 00 02 08 00
				15 01 00 00 00 00 02 09 46
				15 01 00 00 00 00 02 0A 46
				15 01 00 00 00 00 02 0D 0B
				15 01 00 00 00 00 02 0E 1D
				15 01 00 00 00 00 02 0F 08
				15 01 00 00 00 00 02 10 53
				15 01 00 00 00 00 02 11 00
				15 01 00 00 00 00 02 12 00
				15 01 00 00 00 00 02 14 01
				15 01 00 00 00 00 02 15 00
				15 01 00 00 00 00 02 16 05
				15 01 00 00 00 00 02 17 04
				15 01 00 00 00 00 02 19 7F
				15 01 00 00 00 00 02 1A FF
				15 01 00 00 00 00 02 1B 0F
				15 01 00 00 00 00 02 1C 00
				15 01 00 00 00 00 02 1D 00
				15 01 00 00 00 00 02 1E 00
				15 01 00 00 00 00 02 1F 07
				15 01 00 00 00 00 02 20 00
				15 01 00 00 00 00 02 21 00
				15 01 00 00 00 00 02 22 55
				15 01 00 00 00 00 02 23 4D
				15 01 00 00 00 00 02 6C 00
				15 01 00 00 00 00 02 6D 00
				15 01 00 00 00 00 02 2D 02
				15 01 00 00 00 00 02 83 02
				15 01 00 00 00 00 02 9E 58
				15 01 00 00 00 00 02 9F 58
				15 01 00 00 00 00 02 A0 41
				15 01 00 00 00 00 02 A2 10
				15 01 00 00 00 00 02 BB 0A
				15 01 00 00 00 00 02 BC 0A
				15 01 00 00 00 00 02 28 01
				15 01 00 00 00 00 02 2F 02
				15 01 00 00 00 00 02 32 08
				15 01 00 00 00 00 02 33 B8
				15 01 00 00 00 00 02 36 02
				15 01 00 00 00 00 02 37 00
				15 01 00 00 00 00 02 43 00
				15 01 00 00 00 00 02 4B 21
				15 01 00 00 00 00 02 4C 03
				15 01 00 00 00 00 02 50 21
				15 01 00 00 00 00 02 51 03
				15 01 00 00 00 00 02 58 21
				15 01 00 00 00 00 02 59 03
				15 01 00 00 00 00 02 5D 21
				15 01 00 00 00 00 02 5E 03
				15 01 00 00 00 00 02 FF 01
				15 01 00 00 00 00 02 FB 01
				15 01 00 00 00 00 02 75 00
				15 01 00 00 00 00 02 76 59
				15 01 00 00 00 00 02 77 00
				15 01 00 00 00 00 02 78 61
				15 01 00 00 00 00 02 79 00
				15 01 00 00 00 00 02 7A 72
				15 01 00 00 00 00 02 7B 00
				15 01 00 00 00 00 02 7C 81
				15 01 00 00 00 00 02 7D 00
				15 01 00 00 00 00 02 7E 90
				15 01 00 00 00 00 02 7F 00
				15 01 00 00 00 00 02 80 9E
				15 01 00 00 00 00 02 81 00
				15 01 00 00 00 00 02 82 AB
				15 01 00 00 00 00 02 83 00
				15 01 00 00 00 00 02 84 B7
				15 01 00 00 00 00 02 85 00
				15 01 00 00 00 00 02 86 C2
				15 01 00 00 00 00 02 87 00
				15 01 00 00 00 00 02 88 E8
				15 01 00 00 00 00 02 89 01
				15 01 00 00 00 00 02 8A 0A
				15 01 00 00 00 00 02 8B 01
				15 01 00 00 00 00 02 8C 40
				15 01 00 00 00 00 02 8D 01
				15 01 00 00 00 00 02 8E 6E
				15 01 00 00 00 00 02 8F 01
				15 01 00 00 00 00 02 90 B5
				15 01 00 00 00 00 02 91 02
				15 01 00 00 00 00 02 92 0D
				15 01 00 00 00 00 02 93 02
				15 01 00 00 00 00 02 94 0F
				15 01 00 00 00 00 02 95 02
				15 01 00 00 00 00 02 96 57
				15 01 00 00 00 00 02 97 02
				15 01 00 00 00 00 02 98 9E
				15 01 00 00 00 00 02 99 02
				15 01 00 00 00 00 02 9A CA
				15 01 00 00 00 00 02 9B 03
				15 01 00 00 00 00 02 9C 05
				15 01 00 00 00 00 02 9D 03
				15 01 00 00 00 00 02 9E 2C
				15 01 00 00 00 00 02 9F 03
				15 01 00 00 00 00 02 A0 60
				15 01 00 00 00 00 02 A2 03
				15 01 00 00 00 00 02 A3 71
				15 01 00 00 00 00 02 A4 03
				15 01 00 00 00 00 02 A5 87
				15 01 00 00 00 00 02 A6 03
				15 01 00 00 00 00 02 A7 B8
				15 01 00 00 00 00 02 A9 03
				15 01 00 00 00 00 02 AA C8
				15 01 00 00 00 00 02 AB 03
				15 01 00 00 00 00 02 AC D8
				15 01 00 00 00 00 02 AD 03
				15 01 00 00 00 00 02 AE E8
				15 01 00 00 00 00 02 AF 03
				15 01 00 00 00 00 02 B0 F8
				15 01 00 00 00 00 02 B1 03
				15 01 00 00 00 00 02 B2 FF
				15 01 00 00 00 00 02 B3 00
				15 01 00 00 00 00 02 B4 59
				15 01 00 00 00 00 02 B5 00
				15 01 00 00 00 00 02 B6 61
				15 01 00 00 00 00 02 B7 00
				15 01 00 00 00 00 02 B8 72
				15 01 00 00 00 00 02 B9 00
				15 01 00 00 00 00 02 BA 81
				15 01 00 00 00 00 02 BB 00
				15 01 00 00 00 00 02 BC 90
				15 01 00 00 00 00 02 BD 00
				15 01 00 00 00 00 02 BE 9E
				15 01 00 00 00 00 02 BF 00
				15 01 00 00 00 00 02 C0 AB
				15 01 00 00 00 00 02 C1 00
				15 01 00 00 00 00 02 C2 B7
				15 01 00 00 00 00 02 C3 00
				15 01 00 00 00 00 02 C4 C2
				15 01 00 00 00 00 02 C5 00
				15 01 00 00 00 00 02 C6 E8
				15 01 00 00 00 00 02 C7 01
				15 01 00 00 00 00 02 C8 0A
				15 01 00 00 00 00 02 C9 01
				15 01 00 00 00 00 02 CA 40
				15 01 00 00 00 00 02 CB 01
				15 01 00 00 00 00 02 CC 6E
				15 01 00 00 00 00 02 CD 01
				15 01 00 00 00 00 02 CE B5
				15 01 00 00 00 00 02 CF 02
				15 01 00 00 00 00 02 D0 0D
				15 01 00 00 00 00 02 D1 02
				15 01 00 00 00 00 02 D2 0F
				15 01 00 00 00 00 02 D3 02
				15 01 00 00 00 00 02 D4 57
				15 01 00 00 00 00 02 D5 02
				15 01 00 00 00 00 02 D6 9E
				15 01 00 00 00 00 02 D7 02
				15 01 00 00 00 00 02 D8 CA
				15 01 00 00 00 00 02 D9 03
				15 01 00 00 00 00 02 DA 05
				15 01 00 00 00 00 02 DB 03
				15 01 00 00 00 00 02 DC 2C
				15 01 00 00 00 00 02 DD 03
				15 01 00 00 00 00 02 DE 60
				15 01 00 00 00 00 02 DF 03
				15 01 00 00 00 00 02 E0 71
				15 01 00 00 00 00 02 E1 03
				15 01 00 00 00 00 02 E2 87
				15 01 00 00 00 00 02 E3 03
				15 01 00 00 00 00 02 E4 B8
				15 01 00 00 00 00 02 E5 03
				15 01 00 00 00 00 02 E6 C8
				15 01 00 00 00 00 02 E7 03
				15 01 00 00 00 00 02 E8 D8
				15 01 00 00 00 00 02 E9 03
				15 01 00 00 00 00 02 EA E8
				15 01 00 00 00 00 02 EB 03
				15 01 00 00 00 00 02 EC F8
				15 01 00 00 00 00 02 ED 03
				15 01 00 00 00 00 02 EE FF
				15 01 00 00 00 00 02 EF 00
				15 01 00 00 00 00 02 F0 6E
				15 01 00 00 00 00 02 F1 00
				15 01 00 00 00 00 02 F2 76
				15 01 00 00 00 00 02 F3 00
				15 01 00 00 00 00 02 F4 85
				15 01 00 00 00 00 02 F5 00
				15 01 00 00 00 00 02 F6 92
				15 01 00 00 00 00 02 F7 00
				15 01 00 00 00 00 02 F8 9F
				15 01 00 00 00 00 02 F9 00
				15 01 00 00 00 00 02 FA AB
				15 01 00 00 00 00 02 FF 02
				15 01 00 00 00 00 02 FB 01
				15 01 00 00 00 00 02 00 00
				15 01 00 00 00 00 02 01 B6
				15 01 00 00 00 00 02 02 00
				15 01 00 00 00 00 02 03 C1
				15 01 00 00 00 00 02 04 00
				15 01 00 00 00 00 02 05 CB
				15 01 00 00 00 00 02 06 00
				15 01 00 00 00 00 02 07 EF
				15 01 00 00 00 00 02 08 01
				15 01 00 00 00 00 02 09 0F
				15 01 00 00 00 00 02 0A 01
				15 01 00 00 00 00 02 0B 43
				15 01 00 00 00 00 02 0C 01
				15 01 00 00 00 00 02 0D 6E
				15 01 00 00 00 00 02 0E 01
				15 01 00 00 00 00 02 0F B4
				15 01 00 00 00 00 02 10 02
				15 01 00 00 00 00 02 11 0C
				15 01 00 00 00 00 02 12 02
				15 01 00 00 00 00 02 13 0E
				15 01 00 00 00 00 02 14 02
				15 01 00 00 00 00 02 15 56
				15 01 00 00 00 00 02 16 02
				15 01 00 00 00 00 02 17 9E
				15 01 00 00 00 00 02 18 02
				15 01 00 00 00 00 02 19 CA
				15 01 00 00 00 00 02 1A 03
				15 01 00 00 00 00 02 1B 05
				15 01 00 00 00 00 02 1C 03
				15 01 00 00 00 00 02 1D 2A
				15 01 00 00 00 00 02 1E 03
				15 01 00 00 00 00 02 1F 56
				15 01 00 00 00 00 02 20 03
				15 01 00 00 00 00 02 21 61
				15 01 00 00 00 00 02 22 03
				15 01 00 00 00 00 02 23 6F
				15 01 00 00 00 00 02 24 03
				15 01 00 00 00 00 02 25 7D
				15 01 00 00 00 00 02 26 03
				15 01 00 00 00 00 02 27 8D
				15 01 00 00 00 00 02 28 03
				15 01 00 00 00 00 02 29 96
				15 01 00 00 00 00 02 2A 03
				15 01 00 00 00 00 02 2B A2
				15 01 00 00 00 00 02 2D 03
				15 01 00 00 00 00 02 2F B4
				15 01 00 00 00 00 02 30 03
				15 01 00 00 00 00 02 31 FF
				15 01 00 00 00 00 02 32 00
				15 01 00 00 00 00 02 33 6E
				15 01 00 00 00 00 02 34 00
				15 01 00 00 00 00 02 35 76
				15 01 00 00 00 00 02 36 00
				15 01 00 00 00 00 02 37 85
				15 01 00 00 00 00 02 38 00
				15 01 00 00 00 00 02 39 92
				15 01 00 00 00 00 02 3A 00
				15 01 00 00 00 00 02 3B 9F
				15 01 00 00 00 00 02 3D 00
				15 01 00 00 00 00 02 3F AB
				15 01 00 00 00 00 02 40 00
				15 01 00 00 00 00 02 41 B6
				15 01 00 00 00 00 02 42 00
				15 01 00 00 00 00 02 43 C1
				15 01 00 00 00 00 02 44 00
				15 01 00 00 00 00 02 45 CB
				15 01 00 00 00 00 02 46 00
				15 01 00 00 00 00 02 47 EF
				15 01 00 00 00 00 02 48 01
				15 01 00 00 00 00 02 49 0F
				15 01 00 00 00 00 02 4A 01
				15 01 00 00 00 00 02 4B 43
				15 01 00 00 00 00 02 4C 01
				15 01 00 00 00 00 02 4D 6E
				15 01 00 00 00 00 02 4E 01
				15 01 00 00 00 00 02 4F B4
				15 01 00 00 00 00 02 50 02
				15 01 00 00 00 00 02 51 0C
				15 01 00 00 00 00 02 52 02
				15 01 00 00 00 00 02 53 0E
				15 01 00 00 00 00 02 54 02
				15 01 00 00 00 00 02 55 56
				15 01 00 00 00 00 02 56 02
				15 01 00 00 00 00 02 58 9E
				15 01 00 00 00 00 02 59 02
				15 01 00 00 00 00 02 5A CA
				15 01 00 00 00 00 02 5B 03
				15 01 00 00 00 00 02 5C 05
				15 01 00 00 00 00 02 5D 03
				15 01 00 00 00 00 02 5E 2A
				15 01 00 00 00 00 02 5F 03
				15 01 00 00 00 00 02 60 56
				15 01 00 00 00 00 02 61 03
				15 01 00 00 00 00 02 62 61
				15 01 00 00 00 00 02 63 03
				15 01 00 00 00 00 02 64 6F
				15 01 00 00 00 00 02 65 03
				15 01 00 00 00 00 02 66 7D
				15 01 00 00 00 00 02 67 03
				15 01 00 00 00 00 02 68 8D
				15 01 00 00 00 00 02 69 03
				15 01 00 00 00 00 02 6A 96
				15 01 00 00 00 00 02 6B 03
				15 01 00 00 00 00 02 6C A2
				15 01 00 00 00 00 02 6D 03
				15 01 00 00 00 00 02 6E B4
				15 01 00 00 00 00 02 6F 03
				15 01 00 00 00 00 02 70 FF
				15 01 00 00 00 00 02 71 00
				15 01 00 00 00 00 02 72 00
				15 01 00 00 00 00 02 73 00
				15 01 00 00 00 00 02 74 0E
				15 01 00 00 00 00 02 75 00
				15 01 00 00 00 00 02 76 26
				15 01 00 00 00 00 02 77 00
				15 01 00 00 00 00 02 78 3A
				15 01 00 00 00 00 02 79 00
				15 01 00 00 00 00 02 7A 4C
				15 01 00 00 00 00 02 7B 00
				15 01 00 00 00 00 02 7C 5E
				15 01 00 00 00 00 02 7D 00
				15 01 00 00 00 00 02 7E 6E
				15 01 00 00 00 00 02 7F 00
				15 01 00 00 00 00 02 80 7B
				15 01 00 00 00 00 02 81 00
				15 01 00 00 00 00 02 82 88
				15 01 00 00 00 00 02 83 00
				15 01 00 00 00 00 02 84 B4
				15 01 00 00 00 00 02 85 00
				15 01 00 00 00 00 02 86 DB
				15 01 00 00 00 00 02 87 01
				15 01 00 00 00 00 02 88 17
				15 01 00 00 00 00 02 89 01
				15 01 00 00 00 00 02 8A 4A
				15 01 00 00 00 00 02 8B 01
				15 01 00 00 00 00 02 8C 98
				15 01 00 00 00 00 02 8D 01
				15 01 00 00 00 00 02 8E FC
				15 01 00 00 00 00 02 8F 01
				15 01 00 00 00 00 02 90 FE
				15 01 00 00 00 00 02 91 02
				15 01 00 00 00 00 02 92 4A
				15 01 00 00 00 00 02 93 02
				15 01 00 00 00 00 02 94 93
				15 01 00 00 00 00 02 95 02
				15 01 00 00 00 00 02 96 C0
				15 01 00 00 00 00 02 97 03
				15 01 00 00 00 00 02 98 01
				15 01 00 00 00 00 02 99 03
				15 01 00 00 00 00 02 9A 2F
				15 01 00 00 00 00 02 9B 03
				15 01 00 00 00 00 02 9C 85
				15 01 00 00 00 00 02 9D 03
				15 01 00 00 00 00 02 9E CC
				15 01 00 00 00 00 02 9F 03
				15 01 00 00 00 00 02 A0 D4
				15 01 00 00 00 00 02 A2 03
				15 01 00 00 00 00 02 A3 DC
				15 01 00 00 00 00 02 A4 03
				15 01 00 00 00 00 02 A5 E4
				15 01 00 00 00 00 02 A6 03
				15 01 00 00 00 00 02 A7 EC
				15 01 00 00 00 00 02 A9 03
				15 01 00 00 00 00 02 AA F4
				15 01 00 00 00 00 02 AB 03
				15 01 00 00 00 00 02 AC FC
				15 01 00 00 00 00 02 AD 03
				15 01 00 00 00 00 02 AE FF
				15 01 00 00 00 00 02 AF 00
				15 01 00 00 00 00 02 B0 00
				15 01 00 00 00 00 02 B1 00
				15 01 00 00 00 00 02 B2 0E
				15 01 00 00 00 00 02 B3 00
				15 01 00 00 00 00 02 B4 26
				15 01 00 00 00 00 02 B5 00
				15 01 00 00 00 00 02 B6 3A
				15 01 00 00 00 00 02 B7 00
				15 01 00 00 00 00 02 B8 4C
				15 01 00 00 00 00 02 B9 00
				15 01 00 00 00 00 02 BA 5E
				15 01 00 00 00 00 02 BB 00
				15 01 00 00 00 00 02 BC 6E
				15 01 00 00 00 00 02 BD 00
				15 01 00 00 00 00 02 BE 7B
				15 01 00 00 00 00 02 BF 00
				15 01 00 00 00 00 02 C0 88
				15 01 00 00 00 00 02 C1 00
				15 01 00 00 00 00 02 C2 B4
				15 01 00 00 00 00 02 C3 00
				15 01 00 00 00 00 02 C4 DB
				15 01 00 00 00 00 02 C5 01
				15 01 00 00 00 00 02 C6 17
				15 01 00 00 00 00 02 C7 01
				15 01 00 00 00 00 02 C8 4A
				15 01 00 00 00 00 02 C9 01
				15 01 00 00 00 00 02 CA 98
				15 01 00 00 00 00 02 CB 01
				15 01 00 00 00 00 02 CC FC
				15 01 00 00 00 00 02 CD 01
				15 01 00 00 00 00 02 CE FE
				15 01 00 00 00 00 02 CF 02
				15 01 00 00 00 00 02 D0 4A
				15 01 00 00 00 00 02 D1 02
				15 01 00 00 00 00 02 D2 93
				15 01 00 00 00 00 02 D3 02
				15 01 00 00 00 00 02 D4 C0
				15 01 00 00 00 00 02 D5 03
				15 01 00 00 00 00 02 D6 01
				15 01 00 00 00 00 02 D7 03
				15 01 00 00 00 00 02 D8 2F
				15 01 00 00 00 00 02 D9 03
				15 01 00 00 00 00 02 DA 85
				15 01 00 00 00 00 02 DB 03
				15 01 00 00 00 00 02 DC CC
				15 01 00 00 00 00 02 DD 03
				15 01 00 00 00 00 02 DE D4
				15 01 00 00 00 00 02 DF 03
				15 01 00 00 00 00 02 E0 DC
				15 01 00 00 00 00 02 E1 03
				15 01 00 00 00 00 02 E2 E4
				15 01 00 00 00 00 02 E3 03
				15 01 00 00 00 00 02 E4 EC
				15 01 00 00 00 00 02 E5 03
				15 01 00 00 00 00 02 E6 F4
				15 01 00 00 00 00 02 E7 03
				15 01 00 00 00 00 02 E8 FC
				15 01 00 00 00 00 02 E9 03
				15 01 00 00 00 00 02 EA FF
				15 01 00 00 00 00 02 FF 00
				15 01 00 00 00 00 02 FB 01
				15 01 00 00 00 00 02 C2 08
				15 01 00 00 00 00 02 BA 03
				15 01 00 00 0A 00 02 35 00
				05 01 00 00 32 00 01 11];
		qcom,mdss-dsi-on-command = [05 01 00 00 00 00 01 29];
		qcom,mdss-dsi-off-command = [05 01 00 00 00 00 01 28
				05 01 00 00 78 00 01 10];
		qcom,mdss-dsi-on-command-state = "dsi_hs_mode";
		qcom,mdss-dsi-off-command-state = "dsi_hs_mode";

		somc,mdss-dsi-cabc-early-on-command = [15 01 00 00 00 00 02 FF 04
				15 01 00 00 00 00 02 2A 84
				15 01 00 00 00 00 02 29 99
				15 01 00 00 00 00 02 28 99
				15 01 00 00 00 00 02 27 99
				15 01 00 00 00 00 02 26 AA
				15 01 00 00 00 00 02 25 BB
				15 01 00 00 00 00 02 24 CC
				15 01 00 00 00 00 02 23 DD
				15 01 00 00 00 00 02 22 EE
				15 01 00 00 00 00 02 21 FF
				15 01 00 00 00 00 02 0A 03
				15 01 00 00 00 00 02 32 64
				15 01 00 00 00 00 02 FB 01
				15 01 00 00 00 00 02 FF 00
				15 01 00 00 00 00 02 51 FF
				15 01 00 00 00 00 02 53 2C
				15 01 00 00 00 00 02 55 03];
		somc,mdss-dsi-cabc-late-off-command = [15 01 00 00 00 00 02 51 00
				15 01 00 00 00 00 02 53 00
				15 01 00 00 00 00 02 55 00];
		somc,mdss-dsi-cabc-enabled = <1>;

		qcom,mdss-dsi-h-sync-pulse = <1>;
		qcom,mdss-dsi-traffic-mode = "non_burst_sync_event";
		qcom,mdss-dsi-bllp-eof-power-mode;
		qcom,mdss-dsi-bllp-power-mode;
		qcom,mdss-dsi-lane-0-state;
		qcom,mdss-dsi-lane-1-state;
		qcom,mdss-dsi-lane-2-state;
		qcom,mdss-dsi-lane-3-state;
		qcom,mdss-dsi-te-pin-select = <1>;
		qcom,mdss-dsi-te-v-sync-rd-ptr-irq-line = <0x2c>;
		qcom,mdss-dsi-te-v-sync-continue-lines = <0x3c>;
		qcom,mdss-dsi-te-dcs-command = <1>;
		qcom,mdss-dsi-te-check-enable;
		qcom,mdss-dsi-te-using-te-pin;
		qcom,mdss-dsi-panel-timings = [7a 1a 12 00 3e 42 16 20 14 03 04 00];
		qcom,mdss-dsi-t-clk-post = <0x0c>;
		qcom,mdss-dsi-t-clk-pre = <0x1a>;
		qcom,mdss-dsi-bl-min-level = <1>;
		qcom,mdss-dsi-bl-max-level = <4095>;
		qcom,mdss-dsi-dma-trigger = "trigger_sw";
		qcom,mdss-dsi-mdp-trigger = "none";
		qcom,mdss-dsi-bl-pmic-control-type = "bl_ctrl_wled";
		qcom,mdss-dsi-pan-enable-dynamic-fps;
		qcom,mdss-dsi-pan-fps-update = "dfps_suspend_resume_mode";
		qcom,mdss-dsi-reset-sequence = <1 20>, <0 200>, <1 20>;

		qcom,mdss-dsi-panel-clockrate = <428000000>;
		somc,panel-id = [ff ff ff 43];
		somc,driver-ic = <2>;
		somc,mdss-phy-size-mm = <53 94>;
		somc,mdss-dsi-lane-config = [00 c2 45 00 00 00 00 01 75
				00 c2 45 00 00 00 00 01 75
				00 c2 45 00 00 00 00 01 75
				00 c2 45 00 00 00 00 01 75
				00 02 45 00 00 00 00 01 97];
		somc,mdss-dsi-disp-on-in-hs = <0>;
		somc,mdss-dsi-init-from-begin = <1>;

		somc,mdss-dsi-uv-command = [04 01 00 00 00 00 01 DA
				04 01 00 00 00 00 01 DB];
		somc,mdss-dsi-uv-param-type = <4>;
		somc,mdss-dsi-pcc-table-size = <58>;
		somc,mdss-dsi-pcc-table = <
				0x00 0x01 0x24 0x27 0x30 0x33 0x6800 0x6f80 0x8000
				0x00 0x02 0x28 0x2B 0x30 0x33 0x6500 0x7100 0x8000
				0x00 0x03 0x18 0x1B 0x2C 0x2F 0x7600 0x7400 0x8000
				0x00 0x04 0x1C 0x1F 0x2C 0x2F 0x7480 0x7580 0x8000
				0x00 0x05 0x20 0x23 0x2C 0x2F 0x7280 0x7500 0x8000
				0x00 0x06 0x24 0x27 0x2C 0x2F 0x6d80 0x7500 0x8000
				0x00 0x07 0x28 0x2B 0x2C 0x2F 0x6780 0x7300 0x8000
				0x00 0x08 0x18 0x1B 0x28 0x2B 0x7a00 0x7680 0x8000
				0x00 0x09 0x1C 0x1F 0x28 0x2B 0x7900 0x7800 0x8000
				0x00 0x0A 0x20 0x23 0x28 0x2B 0x7180 0x7800 0x8000
				0x00 0x0B 0x24 0x27 0x28 0x2B 0x6f00 0x7880 0x8000
				0x00 0x0C 0x28 0x2B 0x28 0x2B 0x6c00 0x7800 0x8000
				0x00 0x0D 0x18 0x1B 0x24 0x27 0x7d80 0x7980 0x8000
				0x00 0x0E 0x1C 0x1F 0x24 0x27 0x7b80 0x7b00 0x8000
				0x00 0x0F 0x20 0x23 0x24 0x27 0x7600 0x7d00 0x8000
				0x00 0x10 0x24 0x27 0x24 0x27 0x7180 0x7b00 0x8000
				0x00 0x11 0x28 0x2B 0x24 0x27 0x7000 0x7d00 0x8000
				0x00 0x12 0x14 0x17 0x20 0x23 0x8000 0x7980 0x7d00
				0x00 0x13 0x18 0x1B 0x20 0x23 0x7f00 0x7b00 0x7d80
				0x00 0x14 0x1C 0x1F 0x20 0x23 0x7c00 0x7c00 0x7c80
				0x00 0x15 0x20 0x23 0x20 0x23 0x7100 0x7b00 0x7d00
				0x00 0x16 0x24 0x27 0x20 0x23 0x7280 0x7d00 0x7e80
				0x00 0x17 0x28 0x2B 0x20 0x23 0x7000 0x7d00 0x7e80
				0x00 0x18 0x14 0x17 0x1C 0x1F 0x8000 0x7800 0x7900
				0x00 0x19 0x18 0x1B 0x1C 0x1F 0x8000 0x7c00 0x7c00
				0xFF 0x00 0x1C 0x1F 0x1C 0x1F 0x8000 0x8000 0x8000
				0x00 0x1A 0x20 0x23 0x1C 0x1F 0x7a80 0x8000 0x7e80
				0x00 0x1B 0x24 0x27 0x1C 0x1F 0x7680 0x8000 0x7d80
				0x00 0x1C 0x28 0x2B 0x1C 0x1F 0x7300 0x8000 0x7f00
				0x00 0x1D 0x14 0x17 0x18 0x1B 0x8000 0x7800 0x7580
				0x00 0x1E 0x18 0x1B 0x18 0x1B 0x8000 0x7b00 0x7780
				0x00 0x1F 0x1C 0x1F 0x18 0x1B 0x8000 0x8000 0x7c80
				0x00 0x20 0x20 0x23 0x18 0x1B 0x7900 0x8000 0x7980
				0x00 0x21 0x14 0x17 0x14 0x17 0x8000 0x7880 0x7480
				0x00 0x22 0x18 0x1B 0x14 0x17 0x8000 0x7c00 0x7600
				0x00 0x25 0x14 0x17 0x24 0x27 0x8000 0x7400 0x7c80
				0x00 0x26 0x14 0x17 0x28 0x33 0x7880 0x6e00 0x8000
				0x00 0x27 0x18 0x23 0x30 0x33 0x6b80 0x6b00 0x7e00
				0x00 0x28 0x14 0x27 0x34 0x3C 0x6080 0x5f80 0x7780
				0x00 0x29 0x28 0x2B 0x34 0x3C 0x5880 0x6500 0x7c80
				0x00 0x2A 0x28 0x2B 0x14 0x1B 0x5500 0x6600 0x5e80
				0x00 0x2B 0x24 0x27 0x18 0x1B 0x7500 0x8000 0x7200
				0x00 0x2C 0x1C 0x1F 0x14 0x17 0x8000 0x8000 0x7900
				0x00 0x2D 0x20 0x23 0x14 0x17 0x7a80 0x8000 0x7800
				0x00 0x2E 0x24 0x27 0x14 0x17 0x7580 0x8000 0x7780
				0x00 0x2F 0x18 0x1B 0x10 0x13 0x8000 0x7980 0x6f80
				0x00 0x30 0x1C 0x1F 0x10 0x13 0x8000 0x7f80 0x7500
				0x00 0x31 0x20 0x23 0x10 0x13 0x7a80 0x8000 0x7500
				0x00 0x32 0x24 0x27 0x10 0x13 0x7500 0x8000 0x7400
				0x01 0x00 0x00 0x13 0x28 0x3C 0x7c00 0x5f80 0x7380
				0xFF 0x00 0x14 0x27 0x28 0x3C 0x8000 0x8000 0x8000
				0x02 0x00 0x28 0x3C 0x28 0x3C 0x5100 0x6600 0x7380
				0x03 0x00 0x00 0x13 0x14 0x27 0x7d80 0x5f80 0x6300
				0xFF 0x00 0x14 0x27 0x14 0x27 0x8000 0x8000 0x8000
				0x04 0x00 0x28 0x3C 0x14 0x27 0x4e00 0x6600 0x6100
				0x05 0x00 0x00 0x13 0x00 0x13 0x7d00 0x5f00 0x5680
				0x06 0x00 0x14 0x27 0x00 0x13 0x7d80 0x8000 0x6f80
				0x07 0x00 0x28 0x3C 0x00 0x13 0x4d00 0x6600 0x5280>;
	};
};
